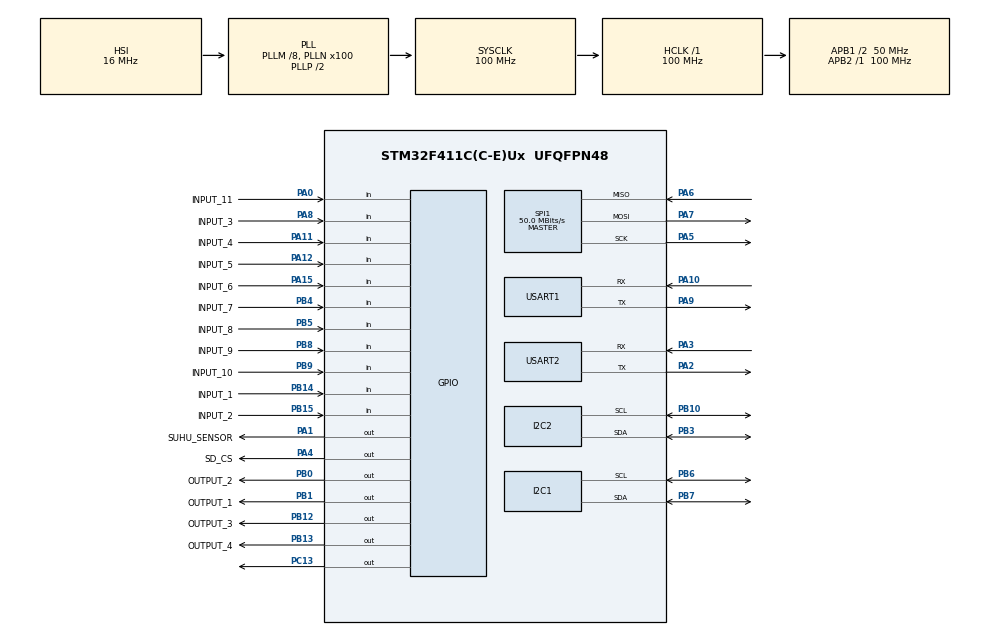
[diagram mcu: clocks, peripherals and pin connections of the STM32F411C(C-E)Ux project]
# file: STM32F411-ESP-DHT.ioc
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FATFS._MAX_SS=4096
FATFS._USE_LFN=1
IWDG.Prescaler=IWDG_PRESCALER_64
IWDG.Reload=999
Mcu.Family=STM32F4
Mcu.Name=STM32F411C(C-E)Ux
Mcu.Package=UFQFPN48
NVIC.I2C1_ER_IRQn=true\:0\:0\:false\:false\:true\:true\:true\:true
NVIC.I2C1_EV_IRQn=true\:0\:0\:false\:false\:true\:true\:true\:true
NVIC.PriorityGroup=NVIC_PRIORITYGROUP_4
NVIC.USART1_IRQn=true\:0\:0\:false\:false\:true\:true\:true\:true
NVIC.USART2_IRQn=true\:0\:0\:false\:false\:true\:true\:true\:true
PA0-WKUP.GPIO_Label=INPUT_11
PA0-WKUP.GPIO_PuPd=GPIO_PULLUP
PA0-WKUP.Signal=GPIO_Input
PA1.GPIO_Label=SUHU_SENSOR
PA1.GPIO_PuPd=GPIO_PULLUP
PA1.Signal=GPIO_Output
PA10.Mode=Asynchronous
PA10.Signal=USART1_RX
PA11.GPIO_Label=INPUT_4
PA11.GPIO_PuPd=GPIO_PULLUP
PA11.Signal=GPIO_Input
PA12.GPIO_Label=INPUT_5
PA12.GPIO_PuPd=GPIO_PULLUP
PA12.Signal=GPIO_Input
PA13.Mode=Serial_Wire
PA13.Signal=SYS_JTMS-SWDIO
PA14.Mode=Serial_Wire
PA14.Signal=SYS_JTCK-SWCLK
PA15.GPIO_Label=INPUT_6
PA15.GPIO_PuPd=GPIO_PULLUP
PA15.Signal=GPIO_Input
PA2.Mode=Asynchronous
PA2.Signal=USART2_TX
PA3.Mode=Asynchronous
PA3.Signal=USART2_RX
PA4.GPIO_Label=SD_CS
PA4.PinState=GPIO_PIN_SET
PA4.Signal=GPIO_Output
PA5.Mode=Full_Duplex_Master
PA5.Signal=SPI1_SCK
PA6.Mode=Full_Duplex_Master
PA6.Signal=SPI1_MISO
PA7.Mode=Full_Duplex_Master
PA7.Signal=SPI1_MOSI
PA8.GPIO_Label=INPUT_3
PA8.GPIO_PuPd=GPIO_PULLUP
PA8.Signal=GPIO_Input
PA9.Mode=Asynchronous
PA9.Signal=USART1_TX
PB0.GPIO_Label=OUTPUT_2
PB0.Signal=GPIO_Output
PB1.GPIO_Label=OUTPUT_1
PB1.Signal=GPIO_Output
PB10.Mode=I2C
PB10.Signal=I2C2_SCL
PB12.GPIO_Label=OUTPUT_3
PB12.Signal=GPIO_Output
PB13.GPIO_Label=OUTPUT_4
PB13.Signal=GPIO_Output
PB14.GPIO_Label=INPUT_1
PB14.GPIO_PuPd=GPIO_PULLUP
PB14.Signal=GPIO_Input
PB15.GPIO_Label=INPUT_2
PB15.GPIO_PuPd=GPIO_PULLUP
PB15.Signal=GPIO_Input
PB3.Mode=I2C
PB3.Signal=I2C2_SDA
PB4.GPIO_Label=INPUT_7
PB4.GPIO_PuPd=GPIO_PULLUP
PB4.Signal=GPIO_Input
PB5.GPIO_Label=INPUT_8
PB5.GPIO_PuPd=GPIO_PULLUP
PB5.Signal=GPIO_Input
PB6.Mode=I2C
PB6.Signal=I2C1_SCL
PB7.Mode=I2C
PB7.Signal=I2C1_SDA
PB8.GPIO_Label=INPUT_9
PB8.GPIO_PuPd=GPIO_PULLUP
PB8.Signal=GPIO_Input
PB9.GPIO_Label=INPUT_10
PB9.GPIO_PuPd=GPIO_PULLUP
PB9.Signal=GPIO_Input
PC13-ANTI_TAMP.Signal=GPIO_Output
PH0\ -\ OSC_IN.Mode=HSE-External-Oscillator
PH0\ -\ OSC_IN.Signal=RCC_OSC_IN
PH1\ -\ OSC_OUT.Mode=HSE-External-Oscillator
PH1\ -\ OSC_OUT.Signal=RCC_OSC_OUT
ProjectManager.HeapSize=0x200
ProjectManager.StackSize=0x400
ProjectManager.TargetToolchain=STM32CubeIDE
RCC.48MHZClocksFreq_Value=50000000
RCC.AHBFreq_Value=100000000
RCC.APB1CLKDivider=RCC_HCLK_DIV2
RCC.APB1Freq_Value=50000000
RCC.APB1TimFreq_Value=100000000
RCC.APB2Freq_Value=100000000
RCC.APB2TimFreq_Value=100000000
RCC.CortexFreq_Value=100000000
RCC.HCLKFreq_Value=100000000
RCC.HSE_VALUE=25000000
RCC.HSI_VALUE=16000000
RCC.LSE_VALUE=32768
RCC.PLLM=8
RCC.PLLN=100
RCC.SYSCLKFreq_VALUE=100000000
RCC.SYSCLKSource=RCC_SYSCLKSOURCE_PLLCLK
RCC.VCOOutputFreq_Value=200000000
SPI1.CalculateBaudRate=50.0 MBits/s
SPI1.Direction=SPI_DIRECTION_2LINES
SPI1.Mode=SPI_MODE_MASTER
SPI1.VirtualType=VM_MASTER
USART1.VirtualMode=VM_ASYNC
USART2.VirtualMode=VM_ASYNC
VP_FATFS_VS_Generic.Mode=User_defined
VP_IWDG_VS_IWDG.Mode=IWDG_Activate
board=custom

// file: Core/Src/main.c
/* USER CODE BEGIN Header */
/**
  ******************************************************************************
  * @file           : main.c
  * @brief          : Main program body
  ******************************************************************************
  * @attention
  *
  * Copyright (c) 2025 STMicroelectronics.
  * All rights reserved.
  *
  * This software is licensed under terms that can be found in the LICENSE file
  * in the root directory of this software component.
  * If no LICENSE file comes with this software, it is provided AS-IS.
  *
  ******************************************************************************
  */
/* USER CODE END Header */
#include "main.h"
#include "fatfs.h"

/* USER CODE BEGIN Includes */
#include <stdio.h>
#include <string.h>
#include <stdlib.h>
#include <stdbool.h>

/* USER CODE END Includes */

/* USER CODE BEGIN PTD */

/* USER CODE BEGIN First_Private_Defines */
#define NUM_ANALOG  4U
#define NUM_INPUTS  11U
#define NUM_OUTPUTS 4U

/* ---- Addon Ekspansi Input (PCF8574, dibaca & dikirim oleh ESP32) ----
 * Konvensi bit gabungan (disepakati dengan firmware ESP32):
 *   bit 0..10  -> I1..I11   (native GPIO STM32, lihat g_inputs[])
 *   bit 11..18 -> I12..I19  (addon PCF8574, dikirim ESP32 via FRAME_TYPE_ADDON)
 */
#define NUM_ADDON_INPUTS       8U
#define ADDON_INPUT_BIT_OFFSET 11U
#define NUM_INPUTS_TOTAL       (ADDON_INPUT_BIT_OFFSET + NUM_ADDON_INPUTS)  /* = 19 */
/* USER CODE END First_Private_Defines */

/* DS3231 RTC Time Structure */
typedef struct
{
    uint8_t  seconds;
    uint8_t  minutes;
    uint8_t  hours;
    uint8_t  dayOfWeek;
    uint8_t  day;
    uint8_t  month;
    uint16_t year;
} DS3231_TimeTypeDef;

/* GPIO Pin Definition */
typedef struct {
    GPIO_TypeDef *Port;
    uint16_t      Pin;
} IO_PinDef_t;

/* Input Index Enum */
typedef enum {
    IN_1 = 0, IN_2, IN_3, IN_4, IN_5,
    IN_6, IN_7, IN_8, IN_9, IN_10, IN_11
} InputId_t;

/* Output Index Enum */
typedef enum {
    OUT_1 = 0, OUT_2, OUT_3, OUT_4
} OutputId_t;

/* Rule Logic Enum */
typedef enum {
    RULE_LOGIC_OFF = 0,
    RULE_LOGIC_OR,
    RULE_LOGIC_AND,
    RULE_LOGIC_NOT
} RuleLogic_t;

/* Rule Definition */
typedef struct {
    RuleLogic_t logic;
    uint8_t     inputs[NUM_INPUTS_TOTAL];  /* referensi input bisa I1..I20 */
    uint8_t     inputCount;
} RuleDef_t;

/* Measurement Structure */
typedef struct {
    uint32_t           seq;
    DS3231_TimeTypeDef rtc;
    int16_t            temp;        		// °C × 10
    int16_t            hum;        			// % × 10
    uint32_t           dig_in;      		// bitmask, bit0..19 = I1..I20 (lihat NUM_INPUTS_TOTAL)
    uint16_t           an_in[NUM_ANALOG];   // 0-255
    uint8_t            q;           		// output bitmask
} Measurement_t;

/* TX Context */
typedef struct {
    uint32_t       seq;
    char           jsonLine[320];
    uint16_t       jsonLen;
    uint8_t        retryCount;
    uint32_t       ackDeadlineMs;
    Measurement_t  measurement;   /* simpan data penuh utk retry TLV identik */
} TxContext_t;

/* Application State */
typedef enum {
    APP_STATE_INIT = 0,
    APP_STATE_SD_MOUNT,
    APP_STATE_LOG_RECOVER,
    APP_STATE_RUN
} AppState_t;

/* TX State */
typedef enum {
    TX_STATE_IDLE = 0,
    TX_STATE_SEND_FRAME,
    TX_STATE_WAIT_TX_COMPLETE,
    TX_STATE_WAIT_ACK,
    TX_STATE_ACK_OK,
    TX_STATE_RETRY_OR_FAIL,
    TX_STATE_MOVE_TO_ERROR
} TxState_t;

typedef struct
{
    uint8_t sensor;
    uint8_t acquisition;
    uint8_t ack;
    uint8_t tx;
    uint8_t sd;
} WatchdogHealth_t;

static WatchdogHealth_t wd;

/* USER CODE END PTD */

/* USER CODE BEGIN PD */
/* ==================== DEBUG CONFIG ====================
 * Master switch untuk SELURUH log debug/monitoring STM32 (mirror dari
 * pola #define DEBUG di firmware ESP32). Ini HANYA mengendalikan log
 * yang keluar lewat UART1 (USB-TTL, dibaca manusia) - TIDAK ada
 * hubungannya dengan komunikasi TLV STM32<->ESP32 di UART2, yang selalu
 * jalan normal terlepas dari nilai DEBUG_ENABLE (lihat UART_Print()
 * vs HAL_UART_Transmit(&huart2, ...) di masing2 fungsi protokol).
 *
 *   DEBUG_ENABLE = 1  -> semua log debug aktif, dikirim ke UART1.
 *   DEBUG_ENABLE = 0  -> seluruh log debug di-strip saat compile time:
 *                        argumen macro (termasuk snprintf & isinya)
 *                        TIDAK dievaluasi sama sekali, jadi tidak ada
 *                        overhead runtime (bukan sekadar if(){} biasa).
 *
 * Cara pakai di kode:
 *   DBG_PRINT("string literal tetap\r\n");
 *   DBG_PRINTF("format %d %s\r\n", angka, teks);
 * Gunakan macro ini utk SEMUA log debug baru, jangan panggil
 * UART_Print()/snprintf(g_debugBuf,...) langsung supaya tetap ikut
 * ter-strip saat DEBUG_ENABLE = 0. */
#define DEBUG_ENABLE 1

#if DEBUG_ENABLE
    #define DBG_PRINT(str)       UART_Print(str)
    #define DBG_PRINTF(fmt, ...) do { snprintf(g_debugBuf, sizeof(g_debugBuf), fmt, ##__VA_ARGS__); \
                                       UART_Print(g_debugBuf); } while (0)
#else
    #define DBG_PRINT(str)       ((void)0)
    #define DBG_PRINTF(fmt, ...) ((void)0)
#endif

/* ==================== TLV FORMAT (UART only) ==================== */
#define TLV_SOF             0x7E

#define TLV_TAG_SEQ         0x01    // uint32 BE
#define TLV_TAG_TEMP        0x02    // int16 BE (°C × 10)
#define TLV_TAG_HUM         0x03    // int16 BE (% × 10)
#define TLV_TAG_DIG_IN      0x04    // uint32 BE (bitmask, bit0..19 = I1..I20 - lihat NUM_INPUTS_TOTAL). BREAKING CHANGE: sebelumnya uint16 (2 byte), sekarang 4 byte - ESP32 wajib update decode-nya juga.
#define TLV_TAG_AN_IN       0x05    // uint16[4] BE
#define TLV_TAG_Q           0x06    // uint8 (bitmask)
#define TLV_TAG_TIMESTAMP   0x07    // uint32 BE

/* Frame types for UART communication */
#define FRAME_TYPE_DATA     0x01
#define FRAME_TYPE_ACK      0x02
#define FRAME_TYPE_RULES    0x03
#define FRAME_TYPE_RTC      0x04
#define FRAME_TYPE_ERROR    0x05   // arah STM32 -> ESP32 (laporan error)
#define FRAME_TYPE_ADDON    0x06   // arah ESP32 -> STM32 (status input addon PCF8574)
#define FRAME_TYPE_READY       0x07   // arah STM32 -> ESP32: STM32 sudah APP_STATE_RUN, siap terima config
#define FRAME_TYPE_RULES_ACK   0x08   // arah STM32 -> ESP32: rules sudah di-parse & diterapkan, payload = jumlah rule

/* TLV tags from ESP32 */
#define TAG_RULE            0x10
#define TAG_RTC_TS          0x20
#define TAG_ADDON_MASK      0x40   // payload 1 byte: bitmask 8 input PCF8574 (aktif=1), lihat FRAME_TYPE_ADDON

/* TLV tags for error report STM32 -> ESP */
#define TLV_TAG_ERR_MODULE  0x30   // u8
#define TLV_TAG_ERR_CODE    0x31   // u8
#define TLV_TAG_ERR_ACTIVE  0x32   // u8 (1 = error, 0 = clear)

/* TLV tag for FRAME_TYPE_RULES_ACK (STM32 -> ESP32) */
#define TAG_RULE_COUNT      0x50   // u8, jumlah rule (Q1..Q4) yg berhasil di-parse & diterapkan

/* I2C Addresses */
#define DS3231_ADDR         (0x68U << 1)
#define ADS1115_ADDR        (0x48U << 1)

/* ADS1115 */
#define ADS_FS_VOLT         4.096f
#define ADC_INPUT_MAX_VOLT  3.3f
#define ADS_READ_PERIOD_MS  100U

/* mid: module id */
#define MOD_RTC   1
#define MOD_DHT   2
#define MOD_ADS   3
#define MOD_SD    4

/* st: status */
#define ST_OK     0
#define ST_ERR    1

/* ec: error code */
#define ERR_NONE      0
#define ERR_TIMEOUT   1
#define ERR_NOT_FOUND 2
#define ERR_CRC       3

/* Buffers */
#define RX_BUF_SIZE             540U
#define UART_FRAME_MAX_LEN      540U
#define JSON_LINE_MAX           320U

/* Timing */
#define INPUT_CHANGE_TIME_MS    500U
#define DELIVERY_TIME_INTERVAL  60000U
#define TX_MAX_RETRY            3U
/* PENTING: nilai ini HARUS lebih besar dari waktu round-trip cloud
 * terlama yang mungkin dipakai ESP32 (lihat sendByTransport() di
 * firmware ESP32). Transport GSM+HTTP butuh ~35-40 detik best-case
 * (HTTPINIT + PARA + prompt + confirm + HTTPACTION 15s + HTTPREAD).
 * Kalau STM32 timeout (retry) SEBELUM ESP32 sempat membalas ACK,
 * STM32 akan kirim ulang TLV yang sama sementara ESP32 masih
 * mem-blocking-proses pengiriman sebelumnya ke cloud -> pengiriman
 * DUPLIKAT ke cloud untuk seq yang sama. 5000ms lama sekali TIDAK
 * cukup untuk mode GSM/HTTP. Sesuaikan angka ini dgn transport
 * TERLAMA yang benar2 dipakai di lapangan; kalau hanya WS/MQTT/TCP
 * (dengan ACK_TIMEOUT_MS versi ESP32 = 3000ms) nilai lama 5000ms
 * cukup - tapi untuk instalasi yang memakai mode GSM/HTTP, WAJIB
 * dinaikkan, dan idempotency di sisi Cloud (dedup by device_id+seq)
 * tetap wajib ada sebagai lapisan pertahanan terakhir. */
#define ACK_TIMEOUT_MS          45000U

/* DHT error reporting delay */
#define DHT_ERROR_ENABLE_DELAY_MS   5000U   // 5 detik setelah boot

/* SD status monitor*/
#define SD_STATUS_INTERVAL_MS   8000U

/* Rules */
#define RULE_MAX_PAYLOAD        420U
#define RULE_STR_MAX_LEN        100U

/* File names*/
#define LOG_FILE_NAME           "log.json"
#define STATUS_FILE_NAME        "status.json"
#define SEQ_FILE_NAME           "seq.dat"      /* counter persisten, independen dari isi queue */
#define LOG_BAD_FILE_NAME       "log_bad.json" /* karantina baris log.json yang gagal di-parse saat recovery */

/* Emergency RAM buffer - fallback TERAKHIR saat SD tidak ter-mount DAN TX
 * sedang sibuk (baru bisa terjadi kalau SD memang lepas/rusak). Ini BUKAN
 * pengganti SD; hanya mencegah 1-2 event terbuang percuma saat window kecil
 * itu terjadi. Kalau SD kembali mount, isi buffer ini di-flush ke log.json. */
#define EMERGENCY_BUF_SLOTS     8U

/* USER CODE END PD */

I2C_HandleTypeDef hi2c1;
I2C_HandleTypeDef hi2c2;

IWDG_HandleTypeDef hiwdg;

SPI_HandleTypeDef hspi1;

UART_HandleTypeDef huart1;
UART_HandleTypeDef huart2;

/* USER CODE BEGIN PV */

/* Sensor data */
static float     g_temp = 0.0f;
static float     g_hum  = 0.0f;
static char      g_debugBuf[384];
static uint32_t  g_bootMs = 0;

/* Input state */
static volatile uint32_t g_inputMaskStable = 0;  /* gabungan I1..I20 (native | addon<<12), dipakai rule engine & dig_in */
static volatile uint16_t g_nativeInputMask = 0;  /* komponen native GPIO saja (I1..I11), didebounce di App_BackgroundSensors */
static volatile uint8_t  g_addonInputMask  = 0;  /* komponen addon PCF8574 (I13..I20), diterima via FRAME_TYPE_ADDON, sudah didebounce di ESP32 */
static volatile uint8_t  g_ruleUpdated     = 0;

/* ---- Addon Type detection ----
 * ESP32 HANYA mengirim frame FRAME_TYPE_ADDON (mask PCF8574) ketika
 * config.addon.type == "ekspansi_input" (lihat handleAddonExpansion() pada
 * firmware ESP32, yang men-skip addonExpansionLoop() untuk addon type
 * "none"/"gsm"). Karena itu, kedatangan frame ini adalah sinyal yang bisa
 * dipakai STM32 untuk mengetahui Addon Type yang sedang aktif TANPA perlu
 * menambah TLV/frame baru pada protokol UART:
 *   - belum pernah terima FRAME_TYPE_ADDON -> Addon Type = None/GSM -> 11 input
 *   - sudah pernah terima FRAME_TYPE_ADDON -> Addon Type = Expansion Input -> 19 input
 */
static volatile uint8_t  g_addonExpansionActive = 0;

/* ADS1115 */
static int16_t  g_anRaw[NUM_ANALOG];
static uint8_t  g_anCache[NUM_ANALOG];
static uint32_t g_adsTick = 0;

/* UART RX - ESP32 */
static uint8_t  g_rxByte;
static uint8_t  g_frameBuf[RX_BUF_SIZE];
static uint16_t g_frameIdx      = 0;
static int16_t  g_expectedLen   = -1;

/* UART RX - RS485/Debug */
static uint8_t  g_rs485RxByte;
static uint8_t  g_rs485Buf[128];
static uint16_t g_rs485Idx = 0;

/* Application state */
static AppState_t g_appState = APP_STATE_SD_MOUNT;

/* SD Card */
static uint8_t  g_sd_mounted = 0;
static uint32_t g_nextSeq    = 1;

/* Flags */
volatile uint8_t g_io_changed_flag = 0;

/* ACK from ESP32 */
volatile uint8_t  g_ack_pending = 0;
volatile uint32_t g_ack_seq     = 0;

/* TX state machine */
static TxState_t   g_txState = TX_STATE_IDLE;
static TxContext_t g_txCtx;
static uint32_t g_pendingLogCount = 0;
static uint32_t g_lastFailedSeq = 0;
static uint32_t g_lastFailedTick = 0;

/* Emergency RAM buffer - lihat komentar EMERGENCY_BUF_SLOTS di atas.
 * HILANG saat power loss (RAM), jadi ini cuma jaring pengaman sekunder;
 * SD card tetap satu-satunya source of truth resmi. */
static Measurement_t g_emergencyBuf[EMERGENCY_BUF_SLOTS];
static uint8_t        g_emergencyCount = 0;

/* Deferred UART Frame Processing - RING BUFFER (bukan 1 slot lagi)
 * Sebelumnya cuma 1 slot: kalau ada frame baru datang sebelum main loop
 * sempat memproses frame sebelumnya (mis. saat STM32 masih di
 * APP_STATE_SD_MOUNT/APP_STATE_LOG_RECOVER dan UART_ProcessPendingFrame()
 * belum dipanggil), frame itu DIBUANG DIAM-DIAM oleh ISR (lihat guard
 * `if (!g_deferredFramePending)` yg lama). Ini salah satu penyebab Rules
 * kadang tidak sampai saat boot bersamaan ESP32+STM32. Sekarang pakai
 * ring buffer kecil supaya beberapa frame yg datang berdekatan (mis. RULES
 * lalu RTC saat boot) tidak saling menimpa. */
#define DEFERRED_FRAME_SLOTS    4U
typedef struct {
    uint8_t  buf[UART_FRAME_MAX_LEN];
    uint16_t len;
    uint8_t  type;
} DeferredFrame_t;
static volatile DeferredFrame_t g_deferredFrames[DEFERRED_FRAME_SLOTS];
static volatile uint8_t g_deferredHead  = 0; /* index utk pop (main loop) */
static volatile uint8_t g_deferredTail  = 0; /* index utk push (ISR) */
static volatile uint8_t g_deferredCount = 0;
static volatile uint32_t g_deferredDroppedCount = 0; /* diagnostik: ring buffer penuh */

/* Error flags */
static uint8_t g_err_rtc = 0;
static uint8_t g_err_dht = 0;
static uint8_t g_err_ads = 0;
static uint8_t g_err_sd  = 0;

/* Input mapping */
static const IO_PinDef_t g_inputs[NUM_INPUTS] =
{
    [IN_1]  = { INPUT_1_GPIO_Port,  INPUT_1_Pin  },
    [IN_2]  = { INPUT_2_GPIO_Port,  INPUT_2_Pin  },
    [IN_3]  = { INPUT_3_GPIO_Port,  INPUT_3_Pin  },
    [IN_4]  = { INPUT_4_GPIO_Port,  INPUT_4_Pin  },
    [IN_5]  = { INPUT_5_GPIO_Port,  INPUT_5_Pin  },
    [IN_6]  = { INPUT_6_GPIO_Port,  INPUT_6_Pin  },
    [IN_7]  = { INPUT_7_GPIO_Port,  INPUT_7_Pin  },
    [IN_8]  = { INPUT_8_GPIO_Port,  INPUT_8_Pin  },
    [IN_9]  = { INPUT_9_GPIO_Port,  INPUT_9_Pin  },
    [IN_10] = { INPUT_10_GPIO_Port, INPUT_10_Pin },
    [IN_11] = { INPUT_11_GPIO_Port, INPUT_11_Pin }
};

/* Output mapping */
static const IO_PinDef_t g_outputs[NUM_OUTPUTS] = {
    [OUT_1] = { OUTPUT_1_GPIO_Port, OUTPUT_1_Pin },
    [OUT_2] = { OUTPUT_2_GPIO_Port, OUTPUT_2_Pin },
    [OUT_3] = { OUTPUT_3_GPIO_Port, OUTPUT_3_Pin },
    [OUT_4] = { OUTPUT_4_GPIO_Port, OUTPUT_4_Pin }
};

/* Rules */
static RuleDef_t g_rules[NUM_OUTPUTS];

/* USER CODE END PV */

void SystemClock_Config(void);
static void MX_GPIO_Init(void);
static void MX_USART1_UART_Init(void);
static void MX_USART2_UART_Init(void);
static void MX_I2C1_Init(void);
static void MX_I2C2_Init(void);
static void MX_SPI1_Init(void);
static void MX_IWDG_Init(void);
/* USER CODE BEGIN PFP */

/* Utility */
static void UART_Print(const char* str);

/* DHT22 */
void DWT_Delay_Init(void);
void delay_us(uint32_t us);
void DHT_SetOutput(void);
void DHT_SetInput(void);
uint8_t DHT_Start(void);
uint8_t DHT_ReadBit(void);
uint8_t DHT_ReadByte(void);
uint8_t DHT22_Read(float *temperature, float *humidity);

/* DS3231 RTC */
static uint8_t bcd2bin(uint8_t val);
static uint8_t bin2bcd(uint8_t val);
uint8_t DS3231_ReadTime(DS3231_TimeTypeDef *t);
uint8_t DS3231_SetTime(const DS3231_TimeTypeDef *t);
static uint8_t IsLeapYear(uint16_t year);
static uint32_t RTC_ToEpochSeconds(const DS3231_TimeTypeDef *t);
static void EpochToRTC(uint32_t epoch, DS3231_TimeTypeDef *t);

/* ADS1115 */
static int16_t ADS1115_ReadRaw(uint8_t ch);
static float ADS1115_ConvertRawToVolt(int16_t raw);
static void ADS_Task(void);
static uint8_t VoltageToPWM_0_255(float voltage);

/* CRC */
static uint16_t CRC16_Modbus(const uint8_t *data, uint16_t len);

/* TLV Encoder (for UART TX to ESP32) */
static size_t TLV_PutU8(uint8_t *buf, uint8_t tag, uint8_t val);
static size_t TLV_PutU16(uint8_t *buf, uint8_t tag, uint16_t val);
static size_t TLV_PutI16(uint8_t *buf, uint8_t tag, int16_t val);
static size_t TLV_PutU32(uint8_t *buf, uint8_t tag, uint32_t val);
static size_t TLV_PutU16Array4(uint8_t *buf, uint8_t tag, const uint16_t arr[4]);
static size_t TLV_EncodeMeasurement(const Measurement_t *m, uint8_t *out, size_t maxLen);
static void SendErrorTLV(uint8_t mid, uint8_t st, uint8_t ec);
static void SendReadyTLV(void);
static void SendRulesAckTLV(uint8_t ruleCount);

/* TLV Parser (from ESP32) */
static uint32_t TLV_ReadU32BE(const uint8_t *p);

/* JSON Encoder/Parser (for SD Card log & debug) */
static size_t JSON_EncodeMeasurement(const Measurement_t *m, char *out, size_t maxLen);
static bool JSON_ParseSeqFromLine(const char *line, uint32_t *outSeq);

/* Rules & Frame RX */
void HAL_UART_RxCpltCallback(UART_HandleTypeDef *huart);
static void Rules_Reset(void);
static void ParseOneRuleString(const char *ruleStr);
static void ParseRulesTLV(const uint8_t *tlv, size_t len);
static void ParseRTCTLV(const uint8_t *tlv, size_t len);
static void ParseACKTLV(const uint8_t *tlv, size_t len);
static void ParseAddonTLV(const uint8_t *tlv, size_t len);
static void RecomputeCombinedInputMask(void);
static inline uint8_t Addon_ActiveInputCount(void);
static uint8_t EvalOutputState(int qIdx, uint32_t inputMask);
static void ApplyRules(uint32_t inputMask);
static void PrintRuleStatus(void);
static void OnFrameReceived(uint8_t *payload, uint16_t len, uint8_t frameType);

/* Logging / ACK helper */
static bool Log_RemoveSeq(uint32_t seqToRemove);
static bool SendMeasurementTLV(const Measurement_t *m);

/* TX state machine */
static void TX_StartNew(const Measurement_t *m);
static void TX_Process(uint32_t now);

/* SD Card & Log (JSON format) */
static void Log_InitRuntime(void);
static bool SD_MountTask(void);
static bool Log_RecoverTask(void);
static bool Log_AppendJSON(const char *jsonLine);
static bool Seq_LoadPersisted(uint32_t *outSeq);
static bool Seq_Persist(uint32_t nextSeq);
static void Log_QuarantineBadLines(void);
static void Emergency_Push(const Measurement_t *m);
static void Emergency_FlushToSD(void);
static void SD_StatusTask(uint32_t now);

/* Application */
static void App_BackgroundSensors(uint32_t now);
static void App_HandleAcquisition(uint32_t now);
static void Acquire_FillMeasurement(Measurement_t *m, const DS3231_TimeTypeDef *rtc);
static void UART_ProcessPendingFrame(void);

/* Debug */
static void Debug_ErrorJson(uint8_t mid, uint8_t st, uint8_t ec);
static void Debug_PrintMeasurementJSON(const Measurement_t *m, bool byIo);
static void Debug_DumpTLV(const char *prefix, const uint8_t *tlv, size_t len);

static void WD_Service(void);

/* USER CODE END PFP */

/* USER CODE BEGIN 0 */

/* ==================== UTILITY ==================== */
static void UART_Print(const char* str)
{
    HAL_UART_Transmit(&huart1, (uint8_t *)str, strlen(str), 100);
}

static inline void WD_SetSensor(void)
{
    wd.sensor = 1;
}

static inline void WD_SetAcquisition(void)
{
    wd.acquisition = 1;
}

static inline void WD_SetAck(void)
{
    wd.ack = 1;
}

static inline void WD_SetTX(void)
{
    wd.tx = 1;
}

static inline void WD_SetSD(void)
{
    wd.sd = 1;
}

/* USER CODE END 0 */

int main(void)
{

  /* MCU Configuration--------------------------------------------------------*/

  /* Reset of all peripherals, Initializes the Flash interface and the Systick. */
  HAL_Init();

  /* Configure the system clock */
  SystemClock_Config();

  /* USER CODE BEGIN SysInit */

  DWT_Delay_Init();
  g_bootMs = HAL_GetTick();   // simpan waktu boot untuk referensi DHT
  /* USER CODE END SysInit */

  /* Initialize all configured peripherals */
  MX_GPIO_Init();
  MX_USART1_UART_Init();
  MX_USART2_UART_Init();
  MX_I2C1_Init();
  MX_I2C2_Init();
  MX_SPI1_Init();
  MX_FATFS_Init();
  MX_IWDG_Init();
  /* USER CODE BEGIN 2 */

  DBG_PRINT("\r\n");
  DBG_PRINT("============================================\r\n");
  DBG_PRINT("  STM32 IoT Node - TLV/JSON Hybrid v1.0\r\n");
  DBG_PRINT("  UART Comms : TLV Binary\r\n");
  DBG_PRINT("  SD Card    : JSON (Human-readable)\r\n");
  DBG_PRINT("  Debug      : JSON (Human-readable)\r\n");
  DBG_PRINT("============================================\r\n");

  Log_InitRuntime();
  g_appState = APP_STATE_SD_MOUNT;

  /* USER CODE END 2 */

  /* Infinite loop */
  /* USER CODE BEGIN WHILE */
  while (1)
  {
      uint32_t now = HAL_GetTick();

      switch (g_appState)
      {
      case APP_STATE_SD_MOUNT:
          {
              uint8_t tries = 0;
              while (!g_sd_mounted && tries < 3) {
                  SD_MountTask();
                  HAL_Delay(200); // jeda 200ms antar percobaan awal
                  tries++;
              }
              g_appState = APP_STATE_LOG_RECOVER;
          }
          break;

      case APP_STATE_LOG_RECOVER:
          // Kalau SD sudah ter-mount, lakukan recovery; kalau tidak, skip saja
          if (g_sd_mounted) {
              Log_RecoverTask();
          }
          g_appState = APP_STATE_RUN;
          DBG_PRINT("[APP] Entering RUN state\r\n");
          /* STM32 baru sekarang benar2 siap: UART_ProcessPendingFrame()
             akan mulai dipanggil di iterasi berikutnya. Kabari ESP32
             lewat handshake FRAME_TYPE_READY, supaya ESP32 tahu KAPAN
             aman mengirim Rules - bukan lagi menebak pakai delay tetap
             yg jadi akar penyebab race saat boot bersamaan. */
          SendReadyTLV();
          break;

      case APP_STATE_RUN:
          // Di RUN, kalau belum ada SD, coba mount berkala (user colok saat jalan)
          if (!g_sd_mounted) {
              SD_MountTask();
          }

          App_BackgroundSensors(now);
          WD_SetSensor();

          App_HandleAcquisition(now);
          WD_SetAcquisition();

          UART_ProcessPendingFrame();
          wd.ack = 1;

          TX_Process(now);
          WD_SetTX();

          SD_StatusTask(now);
          WD_SetSD();

          WD_Service();

          break;

      default:
          g_appState = APP_STATE_SD_MOUNT;
          break;
      }

      HAL_Delay(1);
    /* USER CODE END WHILE */

  }
}

void SystemClock_Config(void)
{
  RCC_OscInitTypeDef RCC_OscInitStruct = {0};
  RCC_ClkInitTypeDef RCC_ClkInitStruct = {0};

  /** Configure the main internal regulator output voltage
  */
  __HAL_RCC_PWR_CLK_ENABLE();
  __HAL_PWR_VOLTAGESCALING_CONFIG(PWR_REGULATOR_VOLTAGE_SCALE1);

  /** Initializes the RCC Oscillators according to the specified parameters
  * in the RCC_OscInitTypeDef structure.
  */
  RCC_OscInitStruct.OscillatorType = RCC_OSCILLATORTYPE_HSI|RCC_OSCILLATORTYPE_LSI;
  RCC_OscInitStruct.HSIState = RCC_HSI_ON;
  RCC_OscInitStruct.HSICalibrationValue = RCC_HSICALIBRATION_DEFAULT;
  RCC_OscInitStruct.LSIState = RCC_LSI_ON;
  RCC_OscInitStruct.PLL.PLLState = RCC_PLL_ON;
  RCC_OscInitStruct.PLL.PLLSource = RCC_PLLSOURCE_HSI;
  RCC_OscInitStruct.PLL.PLLM = 8;
  RCC_OscInitStruct.PLL.PLLN = 100;
  RCC_OscInitStruct.PLL.PLLP = RCC_PLLP_DIV2;
  RCC_OscInitStruct.PLL.PLLQ = 4;
  if (HAL_RCC_OscConfig(&RCC_OscInitStruct) != HAL_OK)
  {
    Error_Handler();
  }

  /** Initializes the CPU, AHB and APB buses clocks
  */
  RCC_ClkInitStruct.ClockType = RCC_CLOCKTYPE_HCLK|RCC_CLOCKTYPE_SYSCLK
                              |RCC_CLOCKTYPE_PCLK1|RCC_CLOCKTYPE_PCLK2;
  RCC_ClkInitStruct.SYSCLKSource = RCC_SYSCLKSOURCE_PLLCLK;
  RCC_ClkInitStruct.AHBCLKDivider = RCC_SYSCLK_DIV1;
  RCC_ClkInitStruct.APB1CLKDivider = RCC_HCLK_DIV2;
  RCC_ClkInitStruct.APB2CLKDivider = RCC_HCLK_DIV1;

  if (HAL_RCC_ClockConfig(&RCC_ClkInitStruct, FLASH_LATENCY_3) != HAL_OK)
  {
    Error_Handler();
  }
}

static void MX_I2C1_Init(void)
{

  hi2c1.Instance = I2C1;
  hi2c1.Init.ClockSpeed = 100000;
  hi2c1.Init.DutyCycle = I2C_DUTYCYCLE_2;
  hi2c1.Init.OwnAddress1 = 0;
  hi2c1.Init.AddressingMode = I2C_ADDRESSINGMODE_7BIT;
  hi2c1.Init.DualAddressMode = I2C_DUALADDRESS_DISABLE;
  hi2c1.Init.OwnAddress2 = 0;
  hi2c1.Init.GeneralCallMode = I2C_GENERALCALL_DISABLE;
  hi2c1.Init.NoStretchMode = I2C_NOSTRETCH_DISABLE;
  if (HAL_I2C_Init(&hi2c1) != HAL_OK)
  {
    Error_Handler();
  }

}

static void MX_I2C2_Init(void)
{

  hi2c2.Instance = I2C2;
  hi2c2.Init.ClockSpeed = 100000;
  hi2c2.Init.DutyCycle = I2C_DUTYCYCLE_2;
  hi2c2.Init.OwnAddress1 = 0;
  hi2c2.Init.AddressingMode = I2C_ADDRESSINGMODE_7BIT;
  hi2c2.Init.DualAddressMode = I2C_DUALADDRESS_DISABLE;
  hi2c2.Init.OwnAddress2 = 0;
  hi2c2.Init.GeneralCallMode = I2C_GENERALCALL_DISABLE;
  hi2c2.Init.NoStretchMode = I2C_NOSTRETCH_DISABLE;
  if (HAL_I2C_Init(&hi2c2) != HAL_OK)
  {
    Error_Handler();
  }

}

static void MX_IWDG_Init(void)
{

  hiwdg.Instance = IWDG;
  hiwdg.Init.Prescaler = IWDG_PRESCALER_64;
  hiwdg.Init.Reload = 999;
  if (HAL_IWDG_Init(&hiwdg) != HAL_OK)
  {
    Error_Handler();
  }

}

static void MX_SPI1_Init(void)
{

  /* SPI1 parameter configuration*/
  hspi1.Instance = SPI1;
  hspi1.Init.Mode = SPI_MODE_MASTER;
  hspi1.Init.Direction = SPI_DIRECTION_2LINES;
  hspi1.Init.DataSize = SPI_DATASIZE_8BIT;
  hspi1.Init.CLKPolarity = SPI_POLARITY_LOW;
  hspi1.Init.CLKPhase = SPI_PHASE_1EDGE;
  hspi1.Init.NSS = SPI_NSS_SOFT;
  hspi1.Init.BaudRatePrescaler = SPI_BAUDRATEPRESCALER_2;
  hspi1.Init.FirstBit = SPI_FIRSTBIT_MSB;
  hspi1.Init.TIMode = SPI_TIMODE_DISABLE;
  hspi1.Init.CRCCalculation = SPI_CRCCALCULATION_DISABLE;
  hspi1.Init.CRCPolynomial = 10;
  if (HAL_SPI_Init(&hspi1) != HAL_OK)
  {
    Error_Handler();
  }

}

static void MX_USART1_UART_Init(void)
{

  huart1.Instance = USART1;
  huart1.Init.BaudRate = 115200;
  huart1.Init.WordLength = UART_WORDLENGTH_8B;
  huart1.Init.StopBits = UART_STOPBITS_1;
  huart1.Init.Parity = UART_PARITY_NONE;
  huart1.Init.Mode = UART_MODE_TX_RX;
  huart1.Init.HwFlowCtl = UART_HWCONTROL_NONE;
  huart1.Init.OverSampling = UART_OVERSAMPLING_16;
  if (HAL_UART_Init(&huart1) != HAL_OK)
  {
    Error_Handler();
  }
  /* USER CODE BEGIN USART1_Init 2 */
  HAL_UART_Receive_IT(&huart1, &g_rs485RxByte, 1);

  /* Priority lebih rendah dari USART2 (yg di-set 5,0) - RS485/debug
     tidak boleh starvasi link data kritis ke ESP32 saat dua interrupt
     datang berdekatan. Angka NVIC lebih besar = priority eksekusi
     lebih rendah di Cortex-M. */
  HAL_NVIC_SetPriority(USART1_IRQn, 6, 0);
  HAL_NVIC_EnableIRQ(USART1_IRQn);
  /* USER CODE END USART1_Init 2 */

}

static void MX_USART2_UART_Init(void)
{

  huart2.Instance = USART2;
  huart2.Init.BaudRate = 115200;
  huart2.Init.WordLength = UART_WORDLENGTH_8B;
  huart2.Init.StopBits = UART_STOPBITS_1;
  huart2.Init.Parity = UART_PARITY_NONE;
  huart2.Init.Mode = UART_MODE_TX_RX;
  huart2.Init.HwFlowCtl = UART_HWCONTROL_NONE;
  huart2.Init.OverSampling = UART_OVERSAMPLING_16;
  if (HAL_UART_Init(&huart2) != HAL_OK)
  {
    Error_Handler();
  }
  /* USER CODE BEGIN USART2_Init 2 */
  	HAL_UART_Receive_IT(&huart2, &g_rxByte, 1);

  	HAL_NVIC_SetPriority(USART2_IRQn, 5, 0);
  	HAL_NVIC_EnableIRQ(USART2_IRQn);
  /* USER CODE END USART2_Init 2 */

}

static void MX_GPIO_Init(void)
{
  GPIO_InitTypeDef GPIO_InitStruct = {0};

  /* GPIO Ports Clock Enable */
  __HAL_RCC_GPIOC_CLK_ENABLE();
  __HAL_RCC_GPIOH_CLK_ENABLE();
  __HAL_RCC_GPIOA_CLK_ENABLE();
  __HAL_RCC_GPIOB_CLK_ENABLE();

  /*Configure GPIO pin Output Level */
  HAL_GPIO_WritePin(GPIOC, GPIO_PIN_13, GPIO_PIN_RESET);

  /*Configure GPIO pin Output Level */
  HAL_GPIO_WritePin(SUHU_SENSOR_GPIO_Port, SUHU_SENSOR_Pin, GPIO_PIN_RESET);

  /*Configure GPIO pin Output Level */
  HAL_GPIO_WritePin(SD_CS_GPIO_Port, SD_CS_Pin, GPIO_PIN_SET);

  /*Configure GPIO pin Output Level */
  HAL_GPIO_WritePin(GPIOB, OUTPUT_2_Pin|OUTPUT_1_Pin|OUTPUT_3_Pin|OUTPUT_4_Pin, GPIO_PIN_RESET);

  /*Configure GPIO pin : PC13 */
  GPIO_InitStruct.Pin = GPIO_PIN_13;
  GPIO_InitStruct.Mode = GPIO_MODE_OUTPUT_PP;
  GPIO_InitStruct.Pull = GPIO_NOPULL;
  GPIO_InitStruct.Speed = GPIO_SPEED_FREQ_LOW;
  HAL_GPIO_Init(GPIOC, &GPIO_InitStruct);

  /*Configure GPIO pins : INPUT_11_Pin INPUT_3_Pin INPUT_4_Pin INPUT_5_Pin
                           INPUT_6_Pin */
  GPIO_InitStruct.Pin = INPUT_11_Pin|INPUT_3_Pin|INPUT_4_Pin|INPUT_5_Pin
                          |INPUT_6_Pin;
  GPIO_InitStruct.Mode = GPIO_MODE_INPUT;
  GPIO_InitStruct.Pull = GPIO_PULLUP;
  HAL_GPIO_Init(GPIOA, &GPIO_InitStruct);

  /*Configure GPIO pin : SUHU_SENSOR_Pin */
  GPIO_InitStruct.Pin = SUHU_SENSOR_Pin;
  GPIO_InitStruct.Mode = GPIO_MODE_OUTPUT_PP;
  GPIO_InitStruct.Pull = GPIO_PULLUP;
  GPIO_InitStruct.Speed = GPIO_SPEED_FREQ_LOW;
  HAL_GPIO_Init(SUHU_SENSOR_GPIO_Port, &GPIO_InitStruct);

  /*Configure GPIO pin : SD_CS_Pin */
  GPIO_InitStruct.Pin = SD_CS_Pin;
  GPIO_InitStruct.Mode = GPIO_MODE_OUTPUT_PP;
  GPIO_InitStruct.Pull = GPIO_NOPULL;
  GPIO_InitStruct.Speed = GPIO_SPEED_FREQ_LOW;
  HAL_GPIO_Init(SD_CS_GPIO_Port, &GPIO_InitStruct);

  /*Configure GPIO pins : OUTPUT_2_Pin OUTPUT_1_Pin OUTPUT_3_Pin OUTPUT_4_Pin */
  GPIO_InitStruct.Pin = OUTPUT_2_Pin|OUTPUT_1_Pin|OUTPUT_3_Pin|OUTPUT_4_Pin;
  GPIO_InitStruct.Mode = GPIO_MODE_OUTPUT_PP;
  GPIO_InitStruct.Pull = GPIO_NOPULL;
  GPIO_InitStruct.Speed = GPIO_SPEED_FREQ_LOW;
  HAL_GPIO_Init(GPIOB, &GPIO_InitStruct);

  /*Configure GPIO pins : INPUT_1_Pin INPUT_2_Pin INPUT_7_Pin INPUT_8_Pin
                           INPUT_9_Pin INPUT_10_Pin */
  GPIO_InitStruct.Pin = INPUT_1_Pin|INPUT_2_Pin|INPUT_7_Pin|INPUT_8_Pin
                          |INPUT_9_Pin|INPUT_10_Pin;
  GPIO_InitStruct.Mode = GPIO_MODE_INPUT;
  GPIO_InitStruct.Pull = GPIO_PULLUP;
  HAL_GPIO_Init(GPIOB, &GPIO_InitStruct);

}

/* USER CODE BEGIN 4 */

/* ==================== DWT DELAY ==================== */
void DWT_Delay_Init(void)
{
    CoreDebug->DEMCR |= CoreDebug_DEMCR_TRCENA_Msk;
    DWT->CYCCNT = 0;
    DWT->CTRL |= DWT_CTRL_CYCCNTENA_Msk;
}

void delay_us(uint32_t us)
{
    uint32_t cycles = us * (SystemCoreClock / 1000000);
    uint32_t start = DWT->CYCCNT;
    while ((DWT->CYCCNT - start) < cycles);
}

/* ==================== DHT22 DRIVER ==================== */
void DHT_SetOutput(void)
{
    GPIO_InitTypeDef GPIO_InitStruct = {0};
    GPIO_InitStruct.Pin = SUHU_SENSOR_Pin;
    GPIO_InitStruct.Mode = GPIO_MODE_OUTPUT_PP;
    GPIO_InitStruct.Pull = GPIO_NOPULL;
    GPIO_InitStruct.Speed = GPIO_SPEED_FREQ_LOW;
    HAL_GPIO_Init(SUHU_SENSOR_GPIO_Port, &GPIO_InitStruct);
}

void DHT_SetInput(void)
{
    GPIO_InitTypeDef GPIO_InitStruct = {0};
    GPIO_InitStruct.Pin = SUHU_SENSOR_Pin;
    GPIO_InitStruct.Mode = GPIO_MODE_INPUT;
    GPIO_InitStruct.Pull = GPIO_PULLUP;
    HAL_GPIO_Init(SUHU_SENSOR_GPIO_Port, &GPIO_InitStruct);
}

uint8_t DHT_Start(void)
{
    uint32_t timeout;

    DHT_SetOutput();
    HAL_GPIO_WritePin(SUHU_SENSOR_GPIO_Port, SUHU_SENSOR_Pin, GPIO_PIN_RESET);
    HAL_Delay(2);
    HAL_GPIO_WritePin(SUHU_SENSOR_GPIO_Port, SUHU_SENSOR_Pin, GPIO_PIN_SET);
    delay_us(30);
    DHT_SetInput();

    timeout = 0;
    while (HAL_GPIO_ReadPin(SUHU_SENSOR_GPIO_Port, SUHU_SENSOR_Pin) == GPIO_PIN_SET)
    {
        delay_us(1);
        if (++timeout > 200) return 0;
    }

    timeout = 0;
    while (HAL_GPIO_ReadPin(SUHU_SENSOR_GPIO_Port, SUHU_SENSOR_Pin) == GPIO_PIN_RESET)
    {
        delay_us(1);
        if (++timeout > 200) return 0;
    }

    timeout = 0;
    while (HAL_GPIO_ReadPin(SUHU_SENSOR_GPIO_Port, SUHU_SENSOR_Pin) == GPIO_PIN_SET)
    {
        delay_us(1);
        if (++timeout > 200) return 0;
    }

    return 1;
}

uint8_t DHT_ReadBit(void)
{
    uint8_t bit = 0;
    uint32_t timeout = 0;

    // Tunggu naik dari LOW ke HIGH, tapi dengan timeout
    while (HAL_GPIO_ReadPin(SUHU_SENSOR_GPIO_Port, SUHU_SENSOR_Pin) == GPIO_PIN_RESET)
    {
        delay_us(1);
        if (++timeout > 200) {
            // timeout ~200 us, anggap bit = 0 dan keluar
            return 0;
        }
    }

    delay_us(40);
    if (HAL_GPIO_ReadPin(SUHU_SENSOR_GPIO_Port, SUHU_SENSOR_Pin) == GPIO_PIN_SET)
        bit = 1;

    // Tunggu turun kembali ke LOW, juga dengan timeout
    timeout = 0;
    while (HAL_GPIO_ReadPin(SUHU_SENSOR_GPIO_Port, SUHU_SENSOR_Pin) == GPIO_PIN_SET)
    {
        delay_us(1);
        if (++timeout > 200) {
            break;  // paksa keluar supaya tidak hang
        }
    }

    return bit;
}

uint8_t DHT_ReadByte(void)
{
    uint8_t i, data = 0;
    for (i = 0; i < 8; i++)
    {
        data <<= 1;
        data |= DHT_ReadBit();
    }
    return data;
}

uint8_t DHT22_Read(float *temperature, float *humidity)
{
    uint8_t data[5];

    if (!DHT_Start()) return 0;

    data[0] = DHT_ReadByte();
    data[1] = DHT_ReadByte();
    data[2] = DHT_ReadByte();
    data[3] = DHT_ReadByte();
    data[4] = DHT_ReadByte();

    uint8_t sum = data[0] + data[1] + data[2] + data[3];
    if (sum != data[4]) return 0;

    uint16_t rawHum  = (data[0] << 8) | data[1];
    int16_t  rawTemp = (data[2] << 8) | data[3];

    *humidity = rawHum / 10.0f;

    if (rawTemp & 0x8000)
    {
        rawTemp &= 0x7FFF;
        *temperature = -rawTemp / 10.0f;
    }
    else
    {
        *temperature = rawTemp / 10.0f;
    }

    if (*humidity < 0.0f || *humidity > 100.0f) return 0;
    if (*temperature < -40.0f || *temperature > 80.0f) return 0;

    return 1;
}

/* ==================== I2C RECOVERY ==================== */
static void I2C1_RecoverBus(void)
{
    HAL_I2C_DeInit(&hi2c1);
    MX_I2C1_Init();    // re-init peripheral
}

static void I2C2_RecoverBus(void)
{
    HAL_I2C_DeInit(&hi2c2);
    MX_I2C2_Init();    // re-init peripheral
}

/* Map HAL I2C status -> error code */
static uint8_t I2C_StatusToErrCode(HAL_StatusTypeDef st)
{
    if (st == HAL_TIMEOUT) {
        return ERR_TIMEOUT;
    }
    // HAL_ERROR atau HAL_BUSY -> treat as NOT_FOUND (device NACK / hilang)
    return ERR_NOT_FOUND;
}

/* ==================== DS3231 RTC ==================== */
static uint8_t bcd2bin(uint8_t val)
{
    return (uint8_t)((val >> 4) * 10 + (val & 0x0F));
}

static uint8_t bin2bcd(uint8_t val)
{
    return (uint8_t)(((val / 10) << 4) | (val % 10));
}

uint8_t DS3231_ReadTime(DS3231_TimeTypeDef *t)
{
    uint8_t buf[7];
    HAL_StatusTypeDef st;

    st = HAL_I2C_Mem_Read(&hi2c1, DS3231_ADDR, 0x00, I2C_MEMADD_SIZE_8BIT,
                          buf, 7, 100);
    if (st != HAL_OK) {
        // Coba recovery I2C1 sekali
        I2C1_RecoverBus();
        st = HAL_I2C_Mem_Read(&hi2c1, DS3231_ADDR, 0x00, I2C_MEMADD_SIZE_8BIT,
                              buf, 7, 100);
        if (st != HAL_OK) {
            // Biarkan App_HandleAcquisition yang meng-set Debug_ErrorJson/SendErrorTLV
            return 0;
        }
    }

    t->seconds   = bcd2bin(buf[0] & 0x7F);
    t->minutes   = bcd2bin(buf[1] & 0x7F);
    t->hours     = bcd2bin(buf[2] & 0x3F);
    t->dayOfWeek = bcd2bin(buf[3] & 0x07);
    t->day       = bcd2bin(buf[4] & 0x3F);
    t->month     = bcd2bin(buf[5] & 0x1F);
    t->year      = 2000 + bcd2bin(buf[6]);

    return 1;
}

uint8_t DS3231_SetTime(const DS3231_TimeTypeDef *t)
{
    uint8_t buf[7];

    buf[0] = bin2bcd(t->seconds);
    buf[1] = bin2bcd(t->minutes);
    buf[2] = bin2bcd(t->hours);
    buf[3] = bin2bcd(t->dayOfWeek);
    buf[4] = bin2bcd(t->day);
    buf[5] = bin2bcd(t->month);
    buf[6] = bin2bcd((uint8_t)(t->year - 2000));

    if (HAL_I2C_Mem_Write(&hi2c1, DS3231_ADDR, 0x00, I2C_MEMADD_SIZE_8BIT,
                          buf, 7, 100) != HAL_OK)
    {
        return 0;
    }
    return 1;
}

static uint8_t IsLeapYear(uint16_t year)
{
    return (year % 4U == 0U);
}

static uint32_t RTC_ToEpochSeconds(const DS3231_TimeTypeDef *t)
{
    static const uint8_t days_in_month[12] =
        {31,28,31,30,31,30,31,31,30,31,30,31};

    uint32_t days = 0;

    for (uint16_t y = 2000; y < t->year; y++) {
        days += 365U + (IsLeapYear(y) ? 1U : 0U);
    }

    for (uint8_t m = 1; m < t->month; m++) {
        days += days_in_month[m-1];
        if (m == 2 && IsLeapYear(t->year)) {
            days += 1U;
        }
    }

    days += (uint32_t)(t->day - 1U);

    uint32_t seconds =
        days * 86400UL +
        (uint32_t)t->hours   * 3600UL +
        (uint32_t)t->minutes * 60UL  +
        (uint32_t)t->seconds;

    return seconds;
}

static void EpochToRTC(uint32_t epoch, DS3231_TimeTypeDef *t)
{
    static const uint8_t daysInMonth[12] =
        {31,28,31,30,31,30,31,31,30,31,30,31};

    uint32_t days = epoch / 86400;
    uint32_t secs = epoch % 86400;

    t->hours   = secs / 3600;
    t->minutes = (secs % 3600) / 60;
    t->seconds = secs % 60;

    t->year = 2000;
    while (1) {
        uint16_t daysInYear = 365 + (IsLeapYear(t->year) ? 1 : 0);
        if (days < daysInYear) break;
        days -= daysInYear;
        t->year++;
    }

    t->month = 1;
    while (1) {
        uint8_t dim = daysInMonth[t->month - 1];
        if (t->month == 2 && IsLeapYear(t->year)) dim = 29;
        if (days < dim) break;
        days -= dim;
        t->month++;
    }

    t->day = days + 1;
    t->dayOfWeek = 1;
}

/* ==================== ADS1115 DRIVER ==================== */
static int16_t ADS1115_ReadRaw(uint8_t ch)
{
    uint8_t  cfg[3];
    uint8_t  rx[2];
    uint16_t config;
    HAL_StatusTypeDef st;
    uint8_t ec;   // error code

    config  = 0x8000U;
    config |= (uint16_t)((0x04U + ch) << 12);
    config |= 0x0200U;
    config |= 0x0100U;
    config |= 0x0080U;
    config |= 0x0003U;

    cfg[0] = 0x01;
    cfg[1] = (uint8_t)(config >> 8);
    cfg[2] = (uint8_t)(config & 0xFF);

    // TX config
    st = HAL_I2C_Master_Transmit(&hi2c2, ADS1115_ADDR, cfg, 3, 100);
    if (st != HAL_OK) {
        I2C2_RecoverBus();
        st = HAL_I2C_Master_Transmit(&hi2c2, ADS1115_ADDR, cfg, 3, 100);
    }
    if (st != HAL_OK) {
        if (!g_err_ads) {
            g_err_ads = 1;
            ec = I2C_StatusToErrCode(st);   // ERR_TIMEOUT atau ERR_NOT_FOUND
            Debug_ErrorJson(MOD_ADS, ST_ERR, ec);
            SendErrorTLV(MOD_ADS, ST_ERR, ec);
        }
        return 0;
    }

    HAL_Delay(8);

    // Set register pointer ke 0x00
    cfg[0] = 0x00;
    st = HAL_I2C_Master_Transmit(&hi2c2, ADS1115_ADDR, cfg, 1, 100);
    if (st != HAL_OK) {
        I2C2_RecoverBus();
        st = HAL_I2C_Master_Transmit(&hi2c2, ADS1115_ADDR, cfg, 1, 100);
    }
    if (st != HAL_OK) {
        if (!g_err_ads) {
            g_err_ads = 1;
            ec = I2C_StatusToErrCode(st);
            Debug_ErrorJson(MOD_ADS, ST_ERR, ec);
            SendErrorTLV(MOD_ADS, ST_ERR, ec);
        }
        return 0;
    }

    // Read conversion
    st = HAL_I2C_Master_Receive(&hi2c2, ADS1115_ADDR, rx, 2, 100);
    if (st != HAL_OK) {
        I2C2_RecoverBus();
        st = HAL_I2C_Master_Receive(&hi2c2, ADS1115_ADDR, rx, 2, 100);
    }
    if (st != HAL_OK) {
        if (!g_err_ads) {
            g_err_ads = 1;
            ec = I2C_StatusToErrCode(st);
            Debug_ErrorJson(MOD_ADS, ST_ERR, ec);
            SendErrorTLV(MOD_ADS, ST_ERR, ec);
        }
        return 0;
    }

    // Sampai sini semua OK, kalau sebelumnya error, kirim status OK
    if (g_err_ads) {
        g_err_ads = 0;
        Debug_ErrorJson(MOD_ADS, ST_OK, ERR_NONE);
        SendErrorTLV(MOD_ADS, ST_OK, ERR_NONE);
    }

    return (int16_t)((rx[0] << 8) | rx[1]);
}

static uint8_t VoltageToPWM_0_255(float voltage)
{
    // Pastikan dalam range 0 .. ADC_INPUT_MAX_VOLT
    if (voltage < 0.0f)            voltage = 0.0f;
    if (voltage > ADC_INPUT_MAX_VOLT) voltage = ADC_INPUT_MAX_VOLT;

    // Mapping linier 0..ADC_INPUT_MAX_VOLT -> 0..255
    float scale = voltage / ADC_INPUT_MAX_VOLT;
    uint8_t pwm = (uint8_t)(scale * 255.0f + 0.5f);  // +0.5 untuk pembulatan

    return pwm;
}

static float ADS1115_ConvertRawToVolt(int16_t raw)
{
    float v = (float)raw * ADS_FS_VOLT / 32768.0f;

    // Clamp ke 0 .. ADC_INPUT_MAX_VOLT
    if (v < 0.0f)            v = 0.0f;
    if (v > ADC_INPUT_MAX_VOLT) v = ADC_INPUT_MAX_VOLT;

    return v;
}

static void ADS_Task(void)
{
    uint32_t now = HAL_GetTick();
    if (now - g_adsTick < ADS_READ_PERIOD_MS)
        return;

    g_adsTick = now;

    for (uint8_t ch = 0; ch < NUM_ANALOG; ch++)
    {
        g_anRaw[ch]   = ADS1115_ReadRaw(ch);
        float volt    = ADS1115_ConvertRawToVolt(g_anRaw[ch]);
        g_anCache[ch] = VoltageToPWM_0_255(volt);
    }
}

/* ==================== CRC16 MODBUS ==================== */
static uint16_t CRC16_Modbus(const uint8_t *data, uint16_t len)
{
    uint16_t crc = 0xFFFF;

    for (uint16_t i = 0; i < len; i++)
    {
        crc ^= data[i];
        for (uint8_t j = 0; j < 8; j++)
        {
            if (crc & 0x0001)
                crc = (crc >> 1) ^ 0xA001;
            else
                crc >>= 1;
        }
    }
    return crc;
}

/* ==================== TLV ENCODER (for UART) ==================== */
static size_t TLV_PutU8(uint8_t *buf, uint8_t tag, uint8_t val)
{
    buf[0] = tag;
    buf[1] = 1;
    buf[2] = val;
    return 3;
}

static size_t TLV_PutU16(uint8_t *buf, uint8_t tag, uint16_t val)
{
    buf[0] = tag;
    buf[1] = 2;
    buf[2] = (uint8_t)(val >> 8);
    buf[3] = (uint8_t)(val & 0xFF);
    return 4;
}

static size_t TLV_PutI16(uint8_t *buf, uint8_t tag, int16_t val)
{
    buf[0] = tag;
    buf[1] = 2;
    buf[2] = (uint8_t)((uint16_t)val >> 8);
    buf[3] = (uint8_t)((uint16_t)val & 0xFF);
    return 4;
}

static size_t TLV_PutU32(uint8_t *buf, uint8_t tag, uint32_t val)
{
    buf[0] = tag;
    buf[1] = 4;
    buf[2] = (uint8_t)(val >> 24);
    buf[3] = (uint8_t)(val >> 16);
    buf[4] = (uint8_t)(val >> 8);
    buf[5] = (uint8_t)(val & 0xFF);
    return 6;
}

static size_t TLV_PutU16Array4(uint8_t *buf, uint8_t tag, const uint16_t arr[4])
{
    buf[0] = tag;
    buf[1] = 8;
    for (int i = 0; i < 4; i++) {
        buf[2 + i*2]     = (uint8_t)(arr[i] >> 8);
        buf[2 + i*2 + 1] = (uint8_t)(arr[i] & 0xFF);
    }
    return 10;
}

static size_t TLV_EncodeMeasurement(const Measurement_t *m, uint8_t *out, size_t maxLen)
{
    if (maxLen < 48) return 0;

    size_t idx = 0;

    // Calculate timestamp epoch from RTC
    uint32_t timestamp = RTC_ToEpochSeconds(&m->rtc);

    idx += TLV_PutU32(&out[idx], TLV_TAG_SEQ, m->seq);
    idx += TLV_PutU32(&out[idx], TLV_TAG_TIMESTAMP, timestamp);
    idx += TLV_PutI16(&out[idx], TLV_TAG_TEMP, m->temp);
    idx += TLV_PutI16(&out[idx], TLV_TAG_HUM, m->hum);
    idx += TLV_PutU32(&out[idx], TLV_TAG_DIG_IN, m->dig_in);  // sekarang 4 byte (I1..I20), lihat catatan TLV_TAG_DIG_IN
    idx += TLV_PutU16Array4(&out[idx], TLV_TAG_AN_IN, m->an_in);
    idx += TLV_PutU8(&out[idx], TLV_TAG_Q, m->q);

    return idx;
}

static void SendErrorTLV(uint8_t mid, uint8_t st, uint8_t ec)
{
    uint8_t payload[16];
    size_t idx = 0;

    // mid -> TLV_TAG_ERR_MODULE
    payload[idx++] = TLV_TAG_ERR_MODULE;
    payload[idx++] = 1;
    payload[idx++] = mid;

    // st -> TLV_TAG_ERR_ACTIVE (pakai tag lama untuk "status")
    payload[idx++] = TLV_TAG_ERR_ACTIVE;
    payload[idx++] = 1;
    payload[idx++] = st;

    // ec -> TLV_TAG_ERR_CODE
    payload[idx++] = TLV_TAG_ERR_CODE;
    payload[idx++] = 1;
    payload[idx++] = ec;

    uint8_t frame[32];
    uint16_t fidx = 0;

    frame[fidx++] = TLV_SOF;
    frame[fidx++] = FRAME_TYPE_ERROR;
    frame[fidx++] = (idx >> 8) & 0xFF;
    frame[fidx++] = idx & 0xFF;

    memcpy(&frame[fidx], payload, idx);
    fidx += idx;

    uint16_t crc = CRC16_Modbus(frame, fidx);
    frame[fidx++] = (crc >> 8) & 0xFF;
    frame[fidx++] = crc & 0xFF;

    HAL_UART_Transmit(&huart2, frame, fidx, 100);
}

/* ----------------------------------------------------------------------
   SendReadyTLV()
   Dikirim SEKALI oleh STM32 ke ESP32 begitu STM32 benar2 masuk
   APP_STATE_RUN (SD mount + log recovery selesai, UART draining aktif,
   siap terima konfigurasi Rules). Ini bagian dari handshake sinkronisasi
   startup - ESP32 menunggu frame ini SEBELUM mengirim Rules, bukan lagi
   menebak pakai delay tetap. Payload kosong, keberadaan frame ini sendiri
   yg jadi sinyal. */
static void SendReadyTLV(void)
{
    uint8_t frame[8];
    uint16_t fidx = 0;

    frame[fidx++] = TLV_SOF;
    frame[fidx++] = FRAME_TYPE_READY;
    frame[fidx++] = 0; // len_h
    frame[fidx++] = 0; // len_l, payload kosong

    uint16_t crc = CRC16_Modbus(frame, fidx);
    frame[fidx++] = (crc >> 8) & 0xFF;
    frame[fidx++] = crc & 0xFF;

    HAL_UART_Transmit(&huart2, frame, fidx, 100);
    DBG_PRINT("[SYNC] READY dikirim ke ESP32\r\n");
}

/* ----------------------------------------------------------------------
   SendRulesAckTLV()
   Dikirim STM32 -> ESP32 SEGERA setelah ParseRulesTLV() selesai
   memproses & menerapkan Rules ke g_rules[]. Payload berisi jumlah rule
   yg berhasil di-parse, supaya ESP32 bisa memvalidasi jumlahnya cocok
   dgn yg dikirim (mendeteksi kalau ada TLV yg korup/rule yg gagal
   diparsing tanpa terlihat). Ini menutup requirement "STM32 mengirim
   ACK bahwa seluruh Rules telah diterapkan" & "validasi jumlah Rules
   yang diterima sesuai dgn yg dikirim". */
static void SendRulesAckTLV(uint8_t ruleCount)
{
    uint8_t payload[4];
    size_t idx = 0;

    payload[idx++] = TAG_RULE_COUNT;
    payload[idx++] = 1;
    payload[idx++] = ruleCount;

    uint8_t frame[16];
    uint16_t fidx = 0;

    frame[fidx++] = TLV_SOF;
    frame[fidx++] = FRAME_TYPE_RULES_ACK;
    frame[fidx++] = (idx >> 8) & 0xFF;
    frame[fidx++] = idx & 0xFF;

    memcpy(&frame[fidx], payload, idx);
    fidx += idx;

    uint16_t crc = CRC16_Modbus(frame, fidx);
    frame[fidx++] = (crc >> 8) & 0xFF;
    frame[fidx++] = crc & 0xFF;

    HAL_UART_Transmit(&huart2, frame, fidx, 100);

    DBG_PRINTF(
             "[SYNC] RULES_ACK dikirim, count=%u\r\n", ruleCount);
}

static bool SendMeasurementTLV(const Measurement_t *m)
{
    uint8_t tlvPayload[64];
    size_t tlvLen = TLV_EncodeMeasurement(m, tlvPayload, sizeof(tlvPayload));
    if (tlvLen == 0) {
        DBG_PRINT("[TX] TLV encode failed\r\n");
        return false;
    }

    uint8_t frame[UART_FRAME_MAX_LEN];
    uint16_t idx = 0;

    frame[idx++] = TLV_SOF;
    frame[idx++] = FRAME_TYPE_DATA;
    frame[idx++] = (tlvLen >> 8) & 0xFF;
    frame[idx++] = tlvLen & 0xFF;

    memcpy(&frame[idx], tlvPayload, tlvLen);
    idx += tlvLen;

    uint16_t crc = CRC16_Modbus(frame, idx);
    frame[idx++] = (crc >> 8) & 0xFF;
    frame[idx++] = crc & 0xFF;

    if (HAL_UART_Transmit(&huart2, frame, idx, 200) != HAL_OK) {
        DBG_PRINT("[TX] UART transmit failed\r\n");
        return false;
    }

    DBG_PRINTF(
             "[TX] Sent TLV seq=%lu len=%u\r\n",
             (unsigned long)m->seq, (unsigned)tlvLen);

    return true;
}

/* ==================== TLV PARSER (from ESP32) ==================== */
static uint32_t TLV_ReadU32BE(const uint8_t *p)
{
    return ((uint32_t)p[0] << 24) |
           ((uint32_t)p[1] << 16) |
           ((uint32_t)p[2] << 8)  |
           p[3];
}

/* ==================== JSON ENCODER (for SD & Debug) ==================== */
static size_t JSON_EncodeMeasurement(const Measurement_t *m, char *out, size_t maxLen)
{
    char ts[32];
    char digArr[64];
    char anArr[32];
    char qArr[24];
    char *p;
    int n;

    // 1) Build timestamp string "YYYY-MM-DDTHH:MM:SSZ"
    snprintf(ts, sizeof(ts), "%04u-%02u-%02uT%02u:%02u:%02uZ",
             m->rtc.year, m->rtc.month, m->rtc.day,
             m->rtc.hours, m->rtc.minutes, m->rtc.seconds);

    // 2) Build dig_in array string [1,0,1,0,...]
    // Jumlah elemen mengikuti Addon Type aktif (11 utk None/GSM, 19 utk
    // Expansion Input), identik dgn perilaku buildDigArray() di ESP32.
    uint8_t digCount = Addon_ActiveInputCount();
    p = digArr;
    *p++ = '[';
    for (uint8_t i = 0; i < digCount; i++) {
        uint8_t bit = (m->dig_in & (1U << i)) ? 1 : 0;
        n = snprintf(p, sizeof(digArr) - (p - digArr), "%u%s",
                     bit, (i < digCount - 1) ? "," : "");
        if (n > 0) p += n;
    }
    *p++ = ']';
    *p = '\0';

    // 3) Build an_in array string [255,255,255,255]
    snprintf(anArr, sizeof(anArr), "[%u,%u,%u,%u]",
             m->an_in[0], m->an_in[1], m->an_in[2], m->an_in[3]);

    // 4) Build q array string [0,1,0,1]
    p = qArr;
    *p++ = '[';
    for (uint8_t i = 0; i < NUM_OUTPUTS; i++) {
        uint8_t bit = (m->q & (1U << i)) ? 1 : 0;
        n = snprintf(p, sizeof(qArr) - (p - qArr), "%u%s",
                     bit, (i < NUM_OUTPUTS - 1) ? "," : "");
        if (n > 0) p += n;
    }
    *p++ = ']';
    *p = '\0';

    // 5) Build complete JSON
    int len = snprintf(out, maxLen,
        "{\"timestamp\":\"%s\","
        "\"env\":{\"temp\":%.1f,\"hum\":%.1f},"
        "\"dig_in\":%s,"
        "\"an_in\":%s,"
        "\"q\":%s,"
        "\"seq\":%lu}\n",
        ts,
        m->temp / 10.0f,
        m->hum / 10.0f,
        digArr,
        anArr,
        qArr,
        (unsigned long)m->seq
    );

    if (len < 0 || (size_t)len >= maxLen) return 0;
    return (size_t)len;
}

static bool JSON_ParseSeqFromLine(const char *line, uint32_t *outSeq)
{
    const char *p = strstr(line, "\"seq\":");
    if (!p) return false;

    p += 6;
    *outSeq = (uint32_t)strtoul(p, NULL, 10);
    return (*outSeq > 0);
}

/* ==================== UART CALLBACKS ==================== */
void HAL_UART_RxCpltCallback(UART_HandleTypeDef *huart)
{
    if (huart == &huart2)
    {
        uint8_t b = g_rxByte;

        if (g_frameIdx == 0)
        {
            if (b == TLV_SOF)
            {
                g_frameBuf[0] = b;
                g_frameIdx    = 1;
                g_expectedLen = -1;
            }
        }
        else
        {
            if (g_frameIdx < RX_BUF_SIZE)
            {
                g_frameBuf[g_frameIdx++] = b;
            }
            else
            {
                g_frameIdx    = 0;
                g_expectedLen = -1;
            }

            // After SOF + TYPE + LEN_H + LEN_L (4 bytes)
            if (g_frameIdx == 4)
            {
                uint16_t payloadLen = ((uint16_t)g_frameBuf[2] << 8) | g_frameBuf[3];
                if (payloadLen > RULE_MAX_PAYLOAD)
                {
                    g_frameIdx    = 0;
                    g_expectedLen = -1;
                }
                else
                {
                    g_expectedLen = 4 + payloadLen + 2;
                }
            }

            if (g_expectedLen > 0 && g_frameIdx == g_expectedLen)
            {
                uint16_t payloadLen = ((uint16_t)g_frameBuf[2] << 8) | g_frameBuf[3];

                uint16_t crcRecv = ((uint16_t)g_frameBuf[g_frameIdx-2] << 8) |
                                    g_frameBuf[g_frameIdx-1];
                uint16_t crcCalc = CRC16_Modbus(g_frameBuf, g_frameIdx-2);

                if (crcRecv == crcCalc)
                {
                    uint8_t frameType = g_frameBuf[1];
                    if (g_deferredCount < DEFERRED_FRAME_SLOTS) {
                        memcpy((void*)g_deferredFrames[g_deferredTail].buf, &g_frameBuf[4], payloadLen);
                        g_deferredFrames[g_deferredTail].len  = payloadLen;
                        g_deferredFrames[g_deferredTail].type = frameType;
                        g_deferredTail = (g_deferredTail + 1) % DEFERRED_FRAME_SLOTS;
                        g_deferredCount++;
                    } else {
                        /* Ring buffer penuh (main loop belum sempat drain -
                           harusnya sangat jarang dgn 4 slot). Dibuang dgn
                           jejak counter, BUKAN diam2 tanpa indikasi sama
                           sekali seperti implementasi lama. */
                        g_deferredDroppedCount++;
                    }
                }

                g_frameIdx    = 0;
                g_expectedLen = -1;
            }
        }

        HAL_UART_Receive_IT(&huart2, &g_rxByte, 1);
    }

    if (huart == &huart1)
    {
        uint8_t b = g_rs485RxByte;

        if (g_rs485Idx < sizeof(g_rs485Buf) - 1)
        {
            g_rs485Buf[g_rs485Idx++] = b;
        }

        if (b == '\n')
        {
            g_rs485Buf[g_rs485Idx] = '\0';
            g_rs485Idx = 0;
        }

        HAL_UART_Receive_IT(&huart1, &g_rs485RxByte, 1);
    }
}

/* ==================== RULES ==================== */
static void Rules_Reset(void)
{
    for (int q = 0; q < NUM_OUTPUTS; q++)
    {
        g_rules[q].logic      = RULE_LOGIC_OFF;
        g_rules[q].inputCount = 0;
        memset(g_rules[q].inputs, 0, sizeof(g_rules[q].inputs));
    }
}

static void ParseOneRuleString(const char *ruleStr)
{
    if (ruleStr == NULL || ruleStr[0] != 'Q') return;

    int qNum = atoi(&ruleStr[1]);
    if (qNum < 1 || qNum > (int)NUM_OUTPUTS) return;
    int qIdx = qNum - 1;

    const char *p = strchr(ruleStr, ':');
    if (!p) return;
    p++;

    const char *p2 = strchr(p, ':');
    if (!p2) return;

    char logicStr[8] = {0};
    size_t logicLen = (size_t)(p2 - p);
    if (logicLen >= sizeof(logicStr))
        logicLen = sizeof(logicStr) - 1;
    memcpy(logicStr, p, logicLen);
    logicStr[logicLen] = '\0';

    RuleLogic_t logic = RULE_LOGIC_OFF;
    if      (strcmp(logicStr, "OR")  == 0) logic = RULE_LOGIC_OR;
    else if (strcmp(logicStr, "AND") == 0) logic = RULE_LOGIC_AND;
    else if (strcmp(logicStr, "NOT") == 0) logic = RULE_LOGIC_NOT;

    g_rules[qIdx].logic      = logic;
    g_rules[qIdx].inputCount = 0;

    const char *r = p2 + 1;
    while (*r != '\0')
    {
        if (*r == 'I')
        {
            int inNum = atoi(r + 1);
            /* I1..I11 = native GPIO, I12 = reserved (belum ada GPIO fisik),
             * I13..I20 = addon PCF8574 (lihat NUM_INPUTS_TOTAL) */
            if (inNum >= 1 && inNum <= (int)NUM_INPUTS_TOTAL)
            {
                if (g_rules[qIdx].inputCount < NUM_INPUTS_TOTAL)
                {
                    g_rules[qIdx].inputs[g_rules[qIdx].inputCount++] = (uint8_t)inNum;
                }
            }
            while (*r && *r != ',' && *r != '\0') r++;
        }
        else
        {
            r++;
        }
    }
}

static void ParseRulesTLV(const uint8_t *tlv, size_t len)
{
    Rules_Reset();

    size_t i = 0;
    uint8_t parsedCount = 0;
    while (i + 2 <= len) {
        uint8_t tag = tlv[i];
        uint8_t l   = tlv[i + 1];

        if (i + 2 + l > len) break;

        if (tag == TAG_RULE) {
            char ruleStr[RULE_STR_MAX_LEN];
            size_t copyLen = (l < RULE_STR_MAX_LEN - 1) ? l : (RULE_STR_MAX_LEN - 1);
            memcpy(ruleStr, &tlv[i + 2], copyLen);
            ruleStr[copyLen] = '\0';
            ParseOneRuleString(ruleStr);
            parsedCount++;
        }

        i += 2 + l;
    }

    g_ruleUpdated = 1;

    /* Beri tahu ESP32 bahwa Rules sudah diterapkan + berapa jumlah yg
       berhasil diparsing, supaya ESP32 bisa validasi & retry kalau perlu
       (lihat penjelasan lengkap di SendRulesAckTLV()). */
    SendRulesAckTLV(parsedCount);
}

static void ParseRTCTLV(const uint8_t *tlv, size_t len)
{
    size_t i = 0;
    while (i + 2 <= len) {
        uint8_t tag = tlv[i];
        uint8_t l   = tlv[i + 1];

        if (i + 2 + l > len) break;

        if (tag == TAG_RTC_TS && l == 4) {
            uint32_t epoch = TLV_ReadU32BE(&tlv[i + 2]);
            DS3231_TimeTypeDef t;
            EpochToRTC(epoch, &t);

            if (DS3231_SetTime(&t)) {
                DBG_PRINT("[RTC] Set from ESP32 OK\r\n");
            } else {
                DBG_PRINT("[RTC] Set FAILED\r\n");
            }
        }

        i += 2 + l;
    }
}

static void ParseACKTLV(const uint8_t *tlv, size_t len)
{
    size_t i = 0;
    while (i + 2 <= len) {
        uint8_t tag = tlv[i];
        uint8_t l   = tlv[i + 1];

        if (i + 2 + l > len) break;

        if (tag == TLV_TAG_SEQ && l == 4) {
            g_ack_seq = TLV_ReadU32BE(&tlv[i + 2]);
            g_ack_pending = 1;

            DBG_PRINTF(
                     "[ACK] Received seq=%lu\r\n", (unsigned long)g_ack_seq);
        }

        i += 2 + l;
    }
}

static void RecomputeCombinedInputMask(void)
{
    uint32_t combined = (uint32_t)g_nativeInputMask |
                         ((uint32_t)g_addonInputMask << ADDON_INPUT_BIT_OFFSET);

    if (combined != g_inputMaskStable)
    {
        g_inputMaskStable = combined;
        g_io_changed_flag = 1;
    }
}

/* Jumlah Digital Input yang aktif saat ini, mengikuti Addon Type:
 *   - Expansion Input -> NUM_INPUTS_TOTAL (19)
 *   - None / GSM      -> NUM_INPUTS (11)
 * Dipakai oleh semua jalur yang membentuk array dig_in (log JSON ke SD
 * Card & debug JSON) supaya jumlahnya identik dengan firmware ESP32. */
static inline uint8_t Addon_ActiveInputCount(void)
{
    return g_addonExpansionActive ? (uint8_t)NUM_INPUTS_TOTAL : (uint8_t)NUM_INPUTS;
}

static void ParseAddonTLV(const uint8_t *tlv, size_t len)
{
    size_t i = 0;
    while (i + 2 <= len)
    {
        uint8_t tag = tlv[i];
        uint8_t l   = tlv[i + 1];

        if (i + 2 + l > len) break;

        if (tag == TAG_ADDON_MASK && l == 1)
        {
            uint8_t newAddonMask = tlv[i + 2];

            /* Frame FRAME_TYPE_ADDON hanya pernah dikirim ESP32 ketika
             * Addon Type = Expansion Input, jadi kedatangannya (terlepas
             * dari mask-nya berubah atau tidak) menandai Addon Type aktif. */
            if (!g_addonExpansionActive)
            {
                g_addonExpansionActive = 1;
                DBG_PRINTF(
                         "[ADDON] Expansion Input terdeteksi aktif, Digital Input = %u channel\r\n",
                         (unsigned)NUM_INPUTS_TOTAL);
            }

            if (newAddonMask != g_addonInputMask)
            {
                g_addonInputMask = newAddonMask;
                RecomputeCombinedInputMask();

                DBG_PRINTF(
                         "[ADDON] mask updated from ESP32: 0x%02X\r\n",
                         newAddonMask);
            }
        }

        i += 2 + l;
    }
}

static uint8_t EvalOutputState(int qIdx, uint32_t inputMask)
{
    RuleDef_t *r = &g_rules[qIdx];

    if (r->logic == RULE_LOGIC_OFF || r->inputCount == 0)
        return 0;

    if (r->logic == RULE_LOGIC_NOT)
    {
        uint8_t in = r->inputs[0];
        uint8_t state = (inputMask & (1U << (in - 1))) ? 1 : 0;
        return !state;
    }

    if (r->logic == RULE_LOGIC_OR)
    {
        for (uint8_t i = 0; i < r->inputCount; i++)
        {
            uint8_t in = r->inputs[i];
            if (inputMask & (1U << (in - 1)))
                return 1;
        }
        return 0;
    }

    if (r->logic == RULE_LOGIC_AND)
    {
        for (uint8_t i = 0; i < r->inputCount; i++)
        {
            uint8_t in = r->inputs[i];
            if (!(inputMask & (1U << (in - 1))))
                return 0;
        }
        return 1;
    }

    return 0;
}

static void ApplyRules(uint32_t inputMask)
{
    for (int q = 0; q < NUM_OUTPUTS; q++)
    {
        uint8_t on = EvalOutputState(q, inputMask);
        HAL_GPIO_WritePin(g_outputs[q].Port, g_outputs[q].Pin,
                          on ? GPIO_PIN_SET : GPIO_PIN_RESET);
    }
}

static void PrintRuleStatus(void)
{
    /* Fungsi ini murni debug/monitoring (dump status rule ke UART1),
     * bukan bagian protokol - seluruh isi di-strip saat DEBUG_ENABLE=0
     * supaya loop & snprintf increment di bawah juga tidak jalan sia-sia. */
#if DEBUG_ENABLE
    DBG_PRINT("[RULE] Current configuration:\r\n");

    for (int q = 0; q < NUM_OUTPUTS; q++)
    {
        RuleDef_t *r = &g_rules[q];

        const char *logicName = "OFF";
        if      (r->logic == RULE_LOGIC_OR)  logicName = "OR";
        else if (r->logic == RULE_LOGIC_AND) logicName = "AND";
        else if (r->logic == RULE_LOGIC_NOT) logicName = "NOT";

        int len = snprintf(g_debugBuf, sizeof(g_debugBuf),
                           "  Q%d: %s (", q + 1, logicName);

        for (uint8_t i = 0; i < r->inputCount; i++)
        {
            len += snprintf(g_debugBuf + len, sizeof(g_debugBuf) - len,
                            "I%u%s", r->inputs[i],
                            (i == r->inputCount - 1) ? "" : ",");
        }
        snprintf(g_debugBuf + len, sizeof(g_debugBuf) - len, ")\r\n");
        UART_Print(g_debugBuf);
    }
#endif
}

static void OnFrameReceived(uint8_t *payload, uint16_t len, uint8_t frameType)
{
    DBG_PRINTF(
             "[RX] Frame type=0x%02X len=%u\r\n", frameType, len);

    switch (frameType) {
        case FRAME_TYPE_RULES:
//            Debug_DumpTLV("[RX][RULES]", payload, len);
            ParseRulesTLV(payload, len);
            break;

        case FRAME_TYPE_RTC:
//            Debug_DumpTLV("[RX][RTC]", payload, len);
            ParseRTCTLV(payload, len);
            break;

        case FRAME_TYPE_ACK:
//            Debug_DumpTLV("[RX][ACK]", payload, len);
            ParseACKTLV(payload, len);
            break;

        case FRAME_TYPE_ADDON:
//            Debug_DumpTLV("[RX][ADDON]", payload, len);
            ParseAddonTLV(payload, len);
            break;

        default:
            DBG_PRINT("[RX] Unknown frame type\r\n");
            break;
    }
}

/* ==================== SD CARD & LOG (JSON format) ==================== */
static void Log_InitRuntime(void)
{
    g_sd_mounted = 0;
    g_nextSeq    = 1;
}

static bool SD_MountTask(void)
{
    static uint32_t lastTryMs   = 0;
    static FRESULT  lastFr      = FR_OK;

    if (g_sd_mounted) return true;

    uint32_t now = HAL_GetTick();
    if ((now - lastTryMs) < 1000U) {   // coba tiap 1 detik
        return false;
    }
    lastTryMs = now;

    // Paksa init ulang disk (akan memanggil SD_disk_initialize)
    disk_initialize(0);

    FRESULT fr = f_mount(&USERFatFS, (TCHAR const*)USERPath, 1);
    if (fr == FR_OK) {
        g_sd_mounted = 1;
        lastFr       = fr;

        if (g_err_sd) {
            g_err_sd = 0;
            Debug_ErrorJson(MOD_SD, ST_OK, ERR_NONE);
            SendErrorTLV(MOD_SD, ST_OK, ERR_NONE);
        }
        DBG_PRINT("[SD] Mounted OK\r\n");
        Emergency_FlushToSD();
        return true;
    } else {
        if (!g_err_sd) {
            g_err_sd = 1;
            Debug_ErrorJson(MOD_SD, ST_ERR, ERR_NOT_FOUND);  // kartu / filesystem tidak ditemukan
            SendErrorTLV(MOD_SD, ST_ERR, ERR_NOT_FOUND);
        }

        // Hanya print kalau kode error berubah
        if (fr != lastFr) {
            lastFr = fr;
            DBG_PRINTF(
                     "[SD] Mount ERR=%d\r\n", fr);
        }
    }
    return false;
}

/* ----------------------------------------------------------------------
   Seq_LoadPersisted() / Seq_Persist()

   Counter sequence number DISIMPAN TERPISAH dari isi queue (seq.dat),
   bukan diturunkan semata-mata dari baris yang masih pending di
   log.json. Alasan: begitu semua event ter-ACK dan log.json kosong
   (kondisi NORMAL saat koneksi cloud lancar), scan log.json akan
   selalu menghasilkan maxSeq=0 -> next=1, sehingga nomor urut kembali
   dari awal padahal cloud sudah punya histori jauh di depan. seq.dat
   menjamin monotonic counter tetap benar walau queue kosong;
   log.json tetap dipakai sbg cross-check kedua (fallback) kalau
   seq.dat hilang/corrupt/kartu SD diganti.
   ---------------------------------------------------------------------- */
static bool Seq_LoadPersisted(uint32_t *outSeq)
{
    FIL f;
    if (f_open(&f, SEQ_FILE_NAME, FA_READ | FA_OPEN_EXISTING) != FR_OK) {
        return false;
    }

    char buf[16] = {0};
    UINT br = 0;
    FRESULT fr = f_read(&f, buf, sizeof(buf) - 1, &br);
    f_close(&f);

    if (fr != FR_OK || br == 0) {
        return false;
    }

    buf[br] = '\0';
    uint32_t val = (uint32_t)strtoul(buf, NULL, 10);
    if (val == 0) {
        return false; /* file kosong/corrupt dianggap tidak valid */
    }

    *outSeq = val;
    return true;
}

static bool Seq_Persist(uint32_t nextSeq)
{
    FIL f;
    FRESULT fr = f_open(&f, SEQ_FILE_NAME, FA_WRITE | FA_CREATE_ALWAYS);
    if (fr != FR_OK) {
        DBG_PRINT("[SEQ] persist open failed\r\n");
        return false;
    }

    char buf[16];
    int len = snprintf(buf, sizeof(buf), "%lu", (unsigned long)nextSeq);
    UINT bw = 0;
    fr = f_write(&f, buf, (UINT)len, &bw);
    f_sync(&f);
    f_close(&f);

    if (fr != FR_OK || (int)bw != len) {
        DBG_PRINT("[SEQ] persist write failed\r\n");
        return false;
    }
    return true;
}

/* ----------------------------------------------------------------------
   Log_QuarantineBadLines()

   Baris di log.json yang gagal di-parse (mis. akibat torn write saat
   power loss persis di tengah f_write) SEBELUMNYA hanya di-skip diam2
   oleh Log_GetFirstPendingMeasurement()/Log_RemoveSeq() - baris itu
   tidak pernah terkirim, tidak pernah dihapus, dan event di dalamnya
   HILANG PERMANEN tanpa ada peringatan ke operator.

   Fungsi ini dipanggil sekali saat recovery: baris valid ditulis balik
   ke log.json, baris yang gagal parse dipindah ke log_bad.json supaya
   masih bisa diaudit manual, dan error dilaporkan ke ESP32/UART supaya
   kejadian ini TIDAK diam-diam.
   ---------------------------------------------------------------------- */
static void Log_QuarantineBadLines(void)
{
    FIL src, dstGood, dstBad;
    if (f_open(&src, LOG_FILE_NAME, FA_READ | FA_OPEN_EXISTING) != FR_OK) {
        return;
    }
    if (f_open(&dstGood, "log_tmp.json", FA_WRITE | FA_CREATE_ALWAYS) != FR_OK) {
        f_close(&src);
        return;
    }
    if (f_open(&dstBad, LOG_BAD_FILE_NAME, FA_WRITE | FA_OPEN_APPEND) != FR_OK) {
        f_close(&src);
        f_close(&dstGood);
        return;
    }

    char line[JSON_LINE_MAX];
    uint32_t seq;
    uint32_t badCount = 0;
    UINT bw;

    while (f_gets(line, sizeof(line), &src) != NULL) {
        HAL_IWDG_Refresh(&hiwdg);
        size_t len = strlen(line);
        if (JSON_ParseSeqFromLine(line, &seq)) {
            f_write(&dstGood, line, len, &bw);
        } else if (len > 1) {
            /* line > 1 char supaya baris kosong/newline sisa tidak dianggap "bad" */
            f_write(&dstBad, line, len, &bw);
            badCount++;
        }
    }

    f_sync(&dstGood);
    f_sync(&dstBad);
    f_close(&src);
    f_close(&dstGood);
    f_close(&dstBad);

    if (badCount > 0) {
        DBG_PRINTF(
                 "[LOG] %lu baris korup dikarantina ke %s\r\n",
                 (unsigned long)badCount, LOG_BAD_FILE_NAME);
        SendErrorTLV(MOD_SD, ST_ERR, ERR_CRC);
    }

    /* Ganti log.json dengan versi bersih (hasil rewrite) */
    f_unlink(LOG_FILE_NAME);
    f_rename("log_tmp.json", LOG_FILE_NAME);
}

/* ----------------------------------------------------------------------
   Emergency_Push() / Emergency_FlushToSD()

   Fallback TERAKHIR: kejadian ini hanya bisa muncul saat SD TIDAK
   ter-mount (kartu lepas/rusak) DAN TX_Process sedang sibuk mengurus
   event lain (retry) di saat yang sama. Sebelumnya kombinasi ini
   membuat event baru terbuang total tanpa jejak di manapun (lihat
   TX_StartNew: kalau state != IDLE, event ditolak; kalau SD juga tidak
   mounted, tidak ada log.json untuk menampungnya). Buffer RAM kecil ini
   menahan event tsb sementara, dan begitu SD kembali ter-mount akan
   di-flush jadi baris log.json biasa (lewat jalur normal, ikut serta
   dalam scan Seq/queue seperti event lainnya).

   CATATAN: ini RAM, jadi tetap hilang kalau restart terjadi SEBELUM SD
   kembali. Bukan pengganti SD - hanya menutup celah kecil, bukan
   solusi utama. Kalau buffer penuh (SD mati berkepanjangan), event
   terlama sengaja di-drop dengan log eksplisit (bukan diam2), supaya
   operator sadar kartu SD perlu segera ditangani.
   ---------------------------------------------------------------------- */
static void Emergency_Push(const Measurement_t *m)
{
    if (g_emergencyCount >= EMERGENCY_BUF_SLOTS) {
        DBG_PRINTF(
                 "[EMERGENCY] buffer penuh, seq=%lu DIBUANG (SD mati terlalu lama!)\r\n",
                 (unsigned long)m->seq);
        return;
    }
    g_emergencyBuf[g_emergencyCount++] = *m;
    DBG_PRINTF(
             "[EMERGENCY] seq=%lu ditahan di RAM (SD tidak mounted, TX busy) [%u/%u]\r\n",
             (unsigned long)m->seq, g_emergencyCount, EMERGENCY_BUF_SLOTS);
}

static void Emergency_FlushToSD(void)
{
    if (g_emergencyCount == 0 || !g_sd_mounted) return;

    for (uint8_t i = 0; i < g_emergencyCount; i++) {
        char jsonLine[JSON_LINE_MAX];
        size_t jsonLen = JSON_EncodeMeasurement(&g_emergencyBuf[i], jsonLine, sizeof(jsonLine));
        if (jsonLen > 0 && Log_AppendJSON(jsonLine)) {
            g_pendingLogCount++;
        } else {
            DBG_PRINT("[EMERGENCY] flush ke log.json gagal, data tetap di RAM\r\n");
            return; /* jangan hapus dari buffer kalau gagal tulis */
        }
    }

    DBG_PRINTF(
             "[EMERGENCY] %u event berhasil di-flush ke log.json\r\n", g_emergencyCount);
    g_emergencyCount = 0;
}

static bool Log_RecoverTask(void)
{
    static uint8_t done = 0;
    if (done) return true;
    if (!g_sd_mounted) return false;

    FIL file;
    FRESULT fr;

    // Pastikan log.json ada
    fr = f_open(&file, LOG_FILE_NAME, FA_READ | FA_OPEN_EXISTING);
    if (fr != FR_OK) {
        // Buat file kosong
        fr = f_open(&file, LOG_FILE_NAME, FA_WRITE | FA_CREATE_ALWAYS);
        if (fr != FR_OK) {
            DBG_PRINT("[LOG] create log.json failed\r\n");
            return false;
        }
        f_close(&file);
    } else {
        f_close(&file);
        // Karantina dulu baris yang gagal parse (torn write dsb), supaya
        // event korup tidak diam2 hilang & tidak ikut mengacaukan scan seq.
        Log_QuarantineBadLines();
    }

    // Scan log.json (yg sudah bersih, atau memang baru dibuat kosong)
    // untuk mencari seq maksimum yang masih pending.
    char line[JSON_LINE_MAX];
    uint32_t seq;
    uint32_t maxSeq = 0;
    uint32_t lineCount = 0;

    fr = f_open(&file, LOG_FILE_NAME, FA_READ | FA_OPEN_EXISTING);
    if (fr == FR_OK) {
        while (f_gets(line, sizeof(line), &file) != NULL) {
            HAL_IWDG_Refresh(&hiwdg);
            if (JSON_ParseSeqFromLine(line, &seq)) {
                if (seq > maxSeq) maxSeq = seq;
                lineCount++;
            }
        }
        f_close(&file);
    }
    g_pendingLogCount = lineCount;

    /* ---- Sumber kebenaran GANDA untuk next-seq ----
       1) seq.dat  : counter persisten independen dari isi queue. Ini
                     yg menjamin monotonic tetap benar walau log.json
                     KOSONG (semua event sudah ter-ACK - kondisi
                     NORMAL, bukan edge case langka).
       2) log.json : fallback kalau seq.dat hilang/corrupt/kartu SD
                     baru/diganti. Juga jaring pengaman kalau seq.dat
                     sempat ketinggalan (mis. crash tepat sebelum
                     Seq_Persist tapi sesudah Log_AppendJSON).
       next-seq final = MAX dari kedua sumber - tidak pernah mundur. */
    uint32_t fromCounterFile = 0;
    bool haveCounterFile = Seq_LoadPersisted(&fromCounterFile);
    uint32_t fromLog = (maxSeq == 0) ? 0 : (maxSeq + 1);

    uint32_t resolved = haveCounterFile ? fromCounterFile : 0;
    if (fromLog > resolved) resolved = fromLog;
    if (resolved == 0) resolved = 1;

    g_nextSeq = resolved;

    /* Selalu tulis ulang seq.dat dgn nilai yg sudah diresolusi, supaya
       file ini konsisten lagi kalau tadi hilang/corrupt/ketinggalan. */
    Seq_Persist(g_nextSeq);

    DBG_PRINTF(
             "[LOG] Recovery done, nextSeq=%lu (counter_file=%s val=%lu, log_max+1=%lu), pending=%lu\r\n",
             (unsigned long)g_nextSeq,
             haveCounterFile ? "OK" : "MISSING",
             (unsigned long)fromCounterFile,
             (unsigned long)fromLog,
             (unsigned long)g_pendingLogCount);

    done = 1;
    return true;
}

static bool Log_AppendJSON(const char *jsonLine)
{
    FIL f;
    FRESULT fr = f_open(&f, LOG_FILE_NAME, FA_WRITE | FA_OPEN_APPEND);
    if (fr != FR_OK) {
        DBG_PRINT("[LOG] Open failed\r\n");
        if (!g_err_sd) {
            g_err_sd = 1;
            Debug_ErrorJson(MOD_SD, ST_ERR, ERR_NOT_FOUND);
            SendErrorTLV(MOD_SD, ST_ERR, ERR_NOT_FOUND);
        }
        f_close(&f);  // jaga-jaga
        f_mount(NULL, (TCHAR const*)USERPath, 0); // unmount
        g_sd_mounted = 0;
        return false;
    }

    UINT bw;
    size_t len = strlen(jsonLine);
    fr = f_write(&f, jsonLine, len, &bw);
    f_sync(&f);
    f_close(&f);

    if (fr != FR_OK || bw != len) {
        DBG_PRINT("[LOG] Write failed\r\n");
        if (!g_err_sd) {
            g_err_sd = 1;
            Debug_ErrorJson(MOD_SD, ST_ERR, ERR_CRC);   // treat as data error
            SendErrorTLV(MOD_SD, ST_ERR, ERR_CRC);
        }
        f_close(&f);
        f_mount(NULL, (TCHAR const*)USERPath, 0);
        g_sd_mounted = 0;
        return false;
    }

    if (g_err_sd) {
        g_err_sd = 0;
        Debug_ErrorJson(MOD_SD, ST_OK, ERR_NONE);
        SendErrorTLV(MOD_SD, ST_OK, ERR_NONE);
    }

    return true;
}

static bool Log_RemoveSeq(uint32_t seqToRemove)
{
    FIL f;
    FRESULT fr = f_open(&f, LOG_FILE_NAME, FA_READ | FA_WRITE);
    if (fr != FR_OK) {
        DBG_PRINT("[LOG] Open for remove failed\r\n");
        f_mount(NULL, (TCHAR const*)USERPath, 0);
        g_sd_mounted = 0;
        return false;
    }

    char line[JSON_LINE_MAX];
    uint32_t seq;
    UINT bw;
    DWORD readPos  = 0;
    DWORD writePos = 0;
    bool removed   = false;

    while (1) {
        HAL_IWDG_Refresh(&hiwdg);
        // Posisikan ke offset baca
        fr = f_lseek(&f, readPos);
        if (fr != FR_OK) break;

        // Baca satu baris
        if (f_gets(line, sizeof(line), &f) == NULL) {
            // EOF
            break;
        }

        // Update posisi baca ke setelah baris ini
        readPos = f_tell(&f);

        // Ambil seq
        if (JSON_ParseSeqFromLine(line, &seq) && seq == seqToRemove) {
            // Skip baris ini (tidak ditulis kembali)
            removed = true;
            continue;
        }

        // Tulis ke posisi writePos
        fr = f_lseek(&f, writePos);
        if (fr != FR_OK) break;

        size_t len = strlen(line);
        fr = f_write(&f, line, len, &bw);
        if (fr != FR_OK || bw != len) {
            DBG_PRINT("[LOG] write during remove failed\r\n");
            break;
        }

        writePos += bw;
    }

    // Jika ada baris dihapus, truncate file ke writePos
    if (removed) {
        fr = f_lseek(&f, writePos);
        if (fr == FR_OK) {
            f_truncate(&f);   // truncate di posisi writePos
        }
        if (g_pendingLogCount > 0) g_pendingLogCount--;
        if (seqToRemove == g_lastFailedSeq) {
            g_lastFailedSeq = 0;
        }
    }

    f_sync(&f);
    f_close(&f);

    return removed;
}

static void SD_StatusTask(uint32_t now)
{
    static uint32_t lastCheckMs = 0;

    // Jalan tiap SD_STATUS_INTERVAL_MS (default 3000 ms)
    if ((now - lastCheckMs) < SD_STATUS_INTERVAL_MS) {
        return;
    }
    lastCheckMs = now;

    // Kalau SD belum ter-mount, coba mount
    if (!g_sd_mounted) {
        SD_MountTask();
        return;
    }

    // Ambil waktu sekarang dari RTC
    DS3231_TimeTypeDef rtc;
    if (!DS3231_ReadTime(&rtc)) {
        // Kalau RTC gagal dibaca, tidak update status.json
        return;
    }

    // Bentuk string timestamp ISO: "YYYY-MM-DDTHH:MM:SSZ"
    char ts[32];
    snprintf(ts, sizeof(ts), "%04u-%02u-%02uT%02u:%02u:%02uZ",
             rtc.year, rtc.month, rtc.day,
             rtc.hours, rtc.minutes, rtc.seconds);

    // JSON 1 baris, berisi waktu terakhir online
    // Contoh: {"last_online":"2025-01-08T12:34:56Z"}
    char jsonLine[96];
    int len = snprintf(jsonLine, sizeof(jsonLine),
                       "{\"last_online\":\"%s\"}\r\n", ts);
    if (len <= 0 || len >= (int)sizeof(jsonLine)) {
        return;
    }

    FIL f;
    FRESULT fr = f_open(&f, STATUS_FILE_NAME, FA_WRITE | FA_CREATE_ALWAYS);
    if (fr != FR_OK) {
        DBG_PRINT("[STATUS] Open status.json failed\r\n");
        if (!g_err_sd) {
            g_err_sd = 1;
            Debug_ErrorJson(MOD_SD, ST_ERR, ERR_NOT_FOUND);
            SendErrorTLV(MOD_SD, ST_ERR, ERR_NOT_FOUND);
        }
        // Unmount supaya nanti dicoba mount ulang
        f_mount(NULL, (TCHAR const*)USERPath, 0);
        g_sd_mounted = 0;
        return;
    }

    UINT bw;
    fr = f_write(&f, jsonLine, len, &bw);
    f_sync(&f);
    f_close(&f);

    if (fr != FR_OK || bw != (UINT)len) {
        DBG_PRINT("[STATUS] Write status.json failed\r\n");
        if (!g_err_sd) {
            g_err_sd = 1;
            Debug_ErrorJson(MOD_SD, ST_ERR, ERR_CRC);
            SendErrorTLV(MOD_SD, ST_ERR, ERR_CRC);
        }
        f_mount(NULL, (TCHAR const*)USERPath, 0);
        g_sd_mounted = 0;
        return;
    }

    // Kalau sebelumnya SD error lalu sekarang sukses, kirim status OK
    if (g_err_sd) {
        g_err_sd = 0;
        Debug_ErrorJson(MOD_SD, ST_OK, ERR_NONE);
        SendErrorTLV(MOD_SD, ST_OK, ERR_NONE);
    }

    // (Opsional) debug
    // UART_Print("[STATUS] status.json updated\r\n");
}

static float ParseFloatFromJSON(const char *str, const char *key) {
    const char *p = strstr(str, key);
    if (p) {
        p += strlen(key);
        return atof(p);
    }
    return 0.0f;
}

static bool Log_ParseJSONToMeasurement(const char *json, Measurement_t *m) {
    memset(m, 0, sizeof(Measurement_t));
    if (!JSON_ParseSeqFromLine(json, &m->seq)) return false;

    float temp = ParseFloatFromJSON(json, "\"temp\":");
    float hum = ParseFloatFromJSON(json, "\"hum\":");
    m->temp = (int16_t)(temp * 10.0f);
    m->hum = (int16_t)(hum * 10.0f);

    const char *p = strstr(json, "\"dig_in\":[");
    if (p) {
        p += 10;
        for (int i = 0; i < NUM_INPUTS_TOTAL; i++) {
            if (*p == '1') m->dig_in |= (1U << i);
            p++;
            if (*p == ',') p++;
            else if (*p == ']') break;
        }
    }

    p = strstr(json, "\"an_in\":[");
    if (p) {
        p += 9;
        for (int i = 0; i < NUM_ANALOG; i++) {
            int val;
            if (sscanf(p, "%d", &val) == 1) m->an_in[i] = (uint16_t)val;
            while (*p && *p != ',' && *p != ']') p++;
            if (*p == ',') p++;
        }
    }

    p = strstr(json, "\"q\":[");
    if (p) {
        p += 5;
        for (int i = 0; i < NUM_OUTPUTS; i++) {
            if (*p == '1') m->q |= (1U << i);
            p++;
            if (*p == ',') p++;
            else if (*p == ']') break;
        }
    }

    p = strstr(json, "\"timestamp\":\"");
    if (p) {
        p += 13;
        unsigned int Y, M, D, h, m_time, s;
        if (sscanf(p, "%04u-%02u-%02uT%02u:%02u:%02uZ", &Y, &M, &D, &h, &m_time, &s) == 6) {
            m->rtc.year = Y;
            m->rtc.month = M;
            m->rtc.day = D;
            m->rtc.hours = h;
            m->rtc.minutes = m_time;
            m->rtc.seconds = s;
            m->rtc.dayOfWeek = 1;
        }
    }
    return true;
}

static bool Log_GetFirstPendingMeasurement(Measurement_t *m) {
    if (!g_sd_mounted) return false;
    static FIL f;
    if (f_open(&f, LOG_FILE_NAME, FA_READ | FA_OPEN_EXISTING) != FR_OK) return false;

    static char line[JSON_LINE_MAX];
    bool found = false;
    while (f_gets(line, sizeof(line), &f) != NULL) {
        if (JSON_ParseSeqFromLine(line, &m->seq)) {
            Log_ParseJSONToMeasurement(line, m);
            found = true;
            break;
        }
    }
    f_close(&f);
    return found;
}

/* ==================== APPLICATION ==================== */
static void App_BackgroundSensors(uint32_t now)
{
    static uint8_t  initialized   = 0;
    static uint32_t lastDhtMs     = 0;
    static uint16_t stableMask    = 0;
    static uint16_t lastRawMask   = 0;
    static uint32_t lastChangeMs  = 0;
    static uint32_t lastRtcCheckMs = 0;

    if (!initialized)
    {
        uint16_t mask0 = 0;
        for (uint8_t i = 0; i < NUM_INPUTS; i++) {
            GPIO_PinState s = HAL_GPIO_ReadPin(g_inputs[i].Port, g_inputs[i].Pin);
            if (s == GPIO_PIN_RESET) mask0 |= (1 << i);
        }
        stableMask        = mask0;
        lastRawMask       = mask0;
        g_nativeInputMask = mask0;
        RecomputeCombinedInputMask();
        lastChangeMs      = now;
        lastDhtMs         = now - 2000U;
        initialized       = 1;
    }

    // Update temp/hum every 2s
    if ((now - lastDhtMs) >= 2000U)
    {
        float t_tmp, h_tmp;
        uint8_t ok = DHT22_Read(&t_tmp, &h_tmp);

        if (ok) {
            // Baca SUKSES
            g_temp = t_tmp;
            g_hum  = h_tmp;

            // Jika sebelumnya error, sekarang recover
            if (g_err_dht) {
                g_err_dht = 0;
                Debug_ErrorJson(MOD_DHT, ST_OK, ERR_NONE);
                SendErrorTLV(MOD_DHT, ST_OK, ERR_NONE);
            }
        } else {
            // Baca GAGAL , tunda pelaporan selama 5 detik
            if ((now - g_bootMs) >= DHT_ERROR_ENABLE_DELAY_MS) {
                if (!g_err_dht) {
                    g_err_dht = 1;
                    Debug_ErrorJson(MOD_DHT, ST_ERR, ERR_TIMEOUT);   // baca DHT timeout / gagal
                    SendErrorTLV(MOD_DHT, ST_ERR, ERR_TIMEOUT);
                }
            }
        }

        lastDhtMs = now;
    }

    // ADS background
    ADS_Task();

    // Read RAW inputs
    uint16_t rawMask = 0;
    for (uint8_t i = 0; i < NUM_INPUTS; i++) {
        GPIO_PinState s = HAL_GPIO_ReadPin(g_inputs[i].Port, g_inputs[i].Pin);
        if (s == GPIO_PIN_RESET) rawMask |= (1 << i);
    }

    if (rawMask != lastRawMask) {
        lastRawMask  = rawMask;
        lastChangeMs = now;
    }

    // Debounce 500 ms
    if ((rawMask != stableMask) && ((now - lastChangeMs) >= INPUT_CHANGE_TIME_MS))
    {
        stableMask        = rawMask;
        g_nativeInputMask = stableMask;
        RecomputeCombinedInputMask();
    }

    static uint32_t lastAppliedMask = 0xFFFFFFFFUL;
    if (g_inputMaskStable != lastAppliedMask || g_ruleUpdated)
    {
        ApplyRules(g_inputMaskStable);
        lastAppliedMask = g_inputMaskStable;
    }

    if (g_ruleUpdated)
    {
        PrintRuleStatus();
        g_ruleUpdated = 0;
    }

    /*Update RTC*/
    if ((now - lastRtcCheckMs) >= 2000U) {
        lastRtcCheckMs = now;

        DS3231_TimeTypeDef tmp;
        if (!DS3231_ReadTime(&tmp)) {
            if (!g_err_rtc) {
                g_err_rtc = 1;
                Debug_ErrorJson(MOD_RTC, ST_ERR, ERR_TIMEOUT);
                SendErrorTLV(MOD_RTC, ST_ERR, ERR_TIMEOUT);
            }
        } else {
            if (g_err_rtc) {
                g_err_rtc = 0;
                Debug_ErrorJson(MOD_RTC, ST_OK, ERR_NONE);
                SendErrorTLV(MOD_RTC, ST_OK, ERR_NONE);
            }
        }
    }
}

static void Acquire_FillMeasurement(Measurement_t *m, const DS3231_TimeTypeDef *rtc)
{
    m->seq = g_nextSeq;
    m->rtc = *rtc;

    m->temp = (int16_t)(g_temp * 10.0f);
    m->hum  = (int16_t)(g_hum * 10.0f);

    m->dig_in = g_inputMaskStable;

    for (int i = 0; i < 4; i++) {
        m->an_in[i] = (uint16_t)g_anCache[i];
    }

    m->q = 0;
    for (int i = 0; i < NUM_OUTPUTS; i++) {
        if (HAL_GPIO_ReadPin(g_outputs[i].Port, g_outputs[i].Pin) == GPIO_PIN_SET) {
            m->q |= (1U << i);
        }
    }
}

static void App_HandleAcquisition(uint32_t now)
{
    static uint32_t lastLogTick = 0;
    static uint8_t  initialized = 0;

    bool needLog = false;
    bool byIo    = false;

    // Inisialisasi pertama kali: mulai hitung interval dari waktu boot
    if (!initialized) {
        lastLogTick = now;
        initialized = 1;
    }

    // 1) Trigger: perubahan input (langsung kirim, reset interval)
    if (g_io_changed_flag) {
        g_io_changed_flag = 0;
        needLog = true;
        byIo    = true;
    }

    // 2) Periodik: tiap DELIVERY_TIME_INTERVAL (misalnya 60000 ms)
    if (!needLog && (now - lastLogTick) >= DELIVERY_TIME_INTERVAL) {
        needLog = true;
        byIo    = false;
    }

    if (!needLog) return;

    // Reset base waktu interval ke saat pengiriman ini
    lastLogTick = now;

    // ======= Di bawah ini biarkan persis seperti semula =======

    // 3) Baca RTC
    DS3231_TimeTypeDef rtc;
    if (!DS3231_ReadTime(&rtc)) {
        if (!g_err_rtc) {
            g_err_rtc = 1;
            Debug_ErrorJson(MOD_RTC, ST_ERR, ERR_TIMEOUT);
            SendErrorTLV(MOD_RTC, ST_ERR, ERR_TIMEOUT);
        }
        memset(&rtc, 0, sizeof(rtc));
        rtc.year  = 2000;
        rtc.month = 1;
        rtc.day   = 1;
    } else {
        if (g_err_rtc) {
            g_err_rtc = 0;
            Debug_ErrorJson(MOD_RTC, ST_OK, ERR_NONE);
            SendErrorTLV(MOD_RTC, ST_OK, ERR_NONE);
        }
    }

    // 4) Isi measurement
    Measurement_t m;
    Acquire_FillMeasurement(&m, &rtc);

    // 5) Encode JSON (untuk SD & debug)
    char  jsonLine[JSON_LINE_MAX];
    size_t jsonLen = JSON_EncodeMeasurement(&m, jsonLine, sizeof(jsonLine));
    if (jsonLen == 0) {
        DBG_PRINT("[ACQ] JSON encode failed\r\n");
        return;
    }

    // 6) Debug ke UART selalu (USART1)
    Debug_PrintMeasurementJSON(&m, byIo);

    // 7) Kalau SD ter-mount, simpan ke log.json
    if (g_sd_mounted) {
        if (Log_AppendJSON(jsonLine)) {
            g_pendingLogCount++;
        } else {
            DBG_PRINT("[ACQ] Log append failed\r\n");
        }
    } else {
        // SD tidak ter-mount: kalau TX idle, kirim langsung.
        // Kalau TX SEDANG SIBUK (mis. masih retry event lain), event ini
        // sebelumnya HILANG TOTAL tanpa jejak (tidak masuk log krn SD mati,
        // ditolak TX_StartNew krn busy). Sekarang ditahan dulu di buffer
        // RAM darurat, di-flush ke log.json begitu SD kembali ter-mount.
        if (g_txState == TX_STATE_IDLE) {
            TX_StartNew(&m);
        } else {
            Emergency_Push(&m);
        }
    }

    // 8) Naikkan seq + persist counter (independen dari isi queue,
    //    lihat penjelasan di Seq_Persist()). Frekuensi rendah (per
    //    perubahan IO / tiap 60s) jadi aman utk wear SD card.
    g_nextSeq++;
    Seq_Persist(g_nextSeq);
}

static void UART_ProcessPendingFrame(void) {
    /* Kuras semua slot yg tersedia tiap panggilan (maks DEFERRED_FRAME_SLOTS,
       jumlahnya kecil jadi aman dari sisi waktu eksekusi). Ini memastikan
       kalau beberapa frame sempat menumpuk saat boot (SD_MOUNT/LOG_RECOVER),
       begitu APP_STATE_RUN tercapai semuanya langsung diproses berurutan,
       bukan cuma 1 per loop iterasi. */
    while (g_deferredCount > 0) {
        uint8_t idx = g_deferredHead;
        OnFrameReceived((uint8_t*)g_deferredFrames[idx].buf,
                        g_deferredFrames[idx].len,
                        g_deferredFrames[idx].type);
        g_deferredHead = (g_deferredHead + 1) % DEFERRED_FRAME_SLOTS;

        __disable_irq();
        g_deferredCount--;
        __enable_irq();
    }

    if (g_deferredDroppedCount > 0) {
        DBG_PRINTF(
                 "[UART] %lu frame dibuang (ring buffer sempat penuh)\r\n",
                 (unsigned long)g_deferredDroppedCount);
        g_deferredDroppedCount = 0;
    }
}

/* ----------------------------------------------------------------------
   TX_StartNew()
   Dipanggil dari App_HandleAcquisition() SEBAGAI PENGGANTI panggilan
   langsung ke SendMeasurementTLV(&m). Tidak langsung kirim - hanya
   menyiapkan context dan menyerahkan eksekusi ke TX_Process() yang
   berjalan non-blocking tiap iterasi main loop.

   Kalau TX sebelumnya masih berjalan (state != IDLE), measurement baru
   TIDAK ditembak (supaya tidak menimpa context yang sedang retry/wait-ack).
   Data measurement yang baru tetap sudah aman di log.json (sudah dipanggil
   Log_AppendJSON sebelum titik ini di App_HandleAcquisition), jadi tidak
   ada data yang hilang - hanya pengiriman TLV-nya yang ditunda ke siklus
   App_HandleAcquisition berikutnya.
   ---------------------------------------------------------------------- */
static void TX_StartNew(const Measurement_t *m)
{
    if (g_txState != TX_STATE_IDLE)
    {
        DBG_PRINTF(
                 "[TX] busy (state=%d), seq=%lu tetap di log.json, kirim ditunda\r\n",
                 (int)g_txState, (unsigned long)m->seq);
        return;
    }

    g_txCtx.seq         = m->seq;
    g_txCtx.measurement = *m;          /* copy penuh, dipakai ulang saat retry */
    g_txCtx.retryCount  = 0;
    g_txCtx.jsonLen     = 0;           /* tidak dipakai di jalur TLV, dibiarkan utk kompatibilitas struct */

    g_txState = TX_STATE_SEND_FRAME;
}

/* ----------------------------------------------------------------------
   TX_Process()
   Dipanggil SETIAP iterasi while(1) di main(), tanpa blocking dan tanpa
   HAL_Delay di dalamnya. Mengeksekusi satu state per pemanggilan.

   Alur:
     IDLE            -> menunggu TX_StartNew() dipanggil
     SEND_FRAME      -> kirim TLV via SendMeasurementTLV (re-encode dari
                        g_txCtx.measurement, jadi retry kirim ulang frame
                        yang identik)
     WAIT_TX_COMPLETE-> (di implementasi ini SendMeasurementTLV blocking
                        HAL_UART_Transmit dengan timeout 200ms, sudah
                        cukup singkat - state ini dilewati langsung ke
                        WAIT_ACK. Disediakan di enum utk pengembangan
                        DMA/IT based transmit di masa depan)
     WAIT_ACK        -> polling g_ack_pending (diisi ISR USART2) sampai
                        match seq atau timeout ACK_TIMEOUT_MS
     ACK_OK          -> hapus baris log.json utk seq ini, balik ke IDLE
     RETRY_OR_FAIL   -> increment retryCount, ulang SEND_FRAME kalau
                        masih di bawah TX_MAX_RETRY, kalau tidak pindah
                        ke MOVE_TO_ERROR
     MOVE_TO_ERROR   -> log kegagalan permanen, data TETAP ada di
                        log.json (tidak dihapus - itulah keamanannya),
                        balik ke IDLE supaya measurement berikutnya
                        tidak ikut macet
   ---------------------------------------------------------------------- */
static void TX_Process(uint32_t now)
{
    switch (g_txState)
    {
    case TX_STATE_IDLE:
        if (g_sd_mounted && g_pendingLogCount > 0) {
            Measurement_t pendingM;
            if (Log_GetFirstPendingMeasurement(&pendingM)) {
                if (pendingM.seq == g_lastFailedSeq) {
                    if ((HAL_GetTick() - g_lastFailedTick) < 5000) {
                        break; // Tunggu 5 detik sebelum retry data yang gagal
                    }
                }
                TX_StartNew(&pendingM);
            } else {
                g_pendingLogCount = 0; // Sinkronisasi jika log kosong tapi count > 0
            }
        }
        break;

    case TX_STATE_SEND_FRAME:
        g_ack_pending = 0; // Hapus sisa ACK basi sebelum transmit baru
        if (SendMeasurementTLV(&g_txCtx.measurement))
        {
            g_txCtx.ackDeadlineMs = now + ACK_TIMEOUT_MS;
            g_txState = TX_STATE_WAIT_ACK;
        }
        else
        {
            /* UART_Transmit gagal (HAL_BUSY/HAL_ERROR) - kemungkinan
               line sedang dipakai. Langsung ke retry, bukan ke error,
               karena ini biasanya transient. */
            g_txState = TX_STATE_RETRY_OR_FAIL;
        }
        break;

    case TX_STATE_WAIT_TX_COMPLETE:
        /* Tidak dipakai pada implementasi UART blocking saat ini.
           Disediakan utk migrasi ke HAL_UART_Transmit_IT/DMA nanti -
           pada saat itu state ini menunggu callback TxCpltCallback
           sebelum lanjut ke WAIT_ACK. */
        g_txState = TX_STATE_WAIT_ACK;
        break;

    case TX_STATE_WAIT_ACK:
        if (g_ack_pending && g_ack_seq == g_txCtx.seq)
        {
            g_ack_pending = 0;
            g_txState = TX_STATE_ACK_OK;
        }
        else if ((int32_t)(now - g_txCtx.ackDeadlineMs) >= 0)
        {
            DBG_PRINTF(
                     "[TX] ACK timeout seq=%lu\r\n",
                     (unsigned long)g_txCtx.seq);
            g_txState = TX_STATE_RETRY_OR_FAIL;
        }
        /* kalau ACK datang dengan seq BERBEDA dari yang ditunggu,
           dibiarkan saja di sini - kemungkinan ACK basi dari frame
           sebelumnya yang sudah lewat timeout-nya sendiri. Dibuang
           secara implisit pada iterasi berikutnya karena g_ack_pending
           akan ditimpa ACK baru atau tetap stale (tidak match selamanya
           sampai ada ACK baru yang benar). */
        break;

    case TX_STATE_ACK_OK:
        if (g_sd_mounted)
        {
            bool removed = Log_RemoveSeq(g_txCtx.seq);
            DBG_PRINTF(
                     "[TX] ACK OK seq=%lu, log_removed=%s\r\n",
                     (unsigned long)g_txCtx.seq, removed ? "YES" : "NO");
        }
        else
        {
            DBG_PRINTF(
                     "[TX] ACK OK seq=%lu (no SD mounted)\r\n",
                     (unsigned long)g_txCtx.seq);
        }
        g_txState = TX_STATE_IDLE;
        break;

    case TX_STATE_RETRY_OR_FAIL:
        g_txCtx.retryCount++;
        if (g_txCtx.retryCount < TX_MAX_RETRY)
        {
            DBG_PRINTF(
                     "[TX] retry %u/%u seq=%lu\r\n",
                     g_txCtx.retryCount, TX_MAX_RETRY,
                     (unsigned long)g_txCtx.seq);
            g_txState = TX_STATE_SEND_FRAME;
        }
        else
        {
            g_txState = TX_STATE_MOVE_TO_ERROR;
        }
        break;

    case TX_STATE_MOVE_TO_ERROR:
        /* Data TIDAK dihapus dari log.json - itu poin pentingnya.
           Kegagalan kirim TLV ke ESP32 tidak berarti data hilang;
           tetap tersimpan di SD utk dikirim manual/recovery nanti.
           Kembali ke IDLE supaya measurement BERIKUTNYA (siklus
           App_HandleAcquisition selanjutnya) tidak ikut tersumbat
           oleh kegagalan yang sudah permanen ini. */
        DBG_PRINTF(
                 "[TX] FAILED permanen seq=%lu setelah %u retry, data tetap di log.json\r\n",
                 (unsigned long)g_txCtx.seq, TX_MAX_RETRY);

        g_lastFailedSeq = g_txCtx.seq;
        g_lastFailedTick = now;
        g_txState = TX_STATE_IDLE;
        break;

    default:
        g_txState = TX_STATE_IDLE;
        break;
    }
}

/* ==================== DEBUG ==================== */
static void Debug_ErrorJson(uint8_t mid, uint8_t st, uint8_t ec)
{
#if DEBUG_ENABLE
    // Format baru: {"mid":1,"st":1,"ec":2}
    DBG_PRINTF(
             "[ERR]{\"mid\":%u,\"st\":%u,\"ec\":%u}\r\n",
             mid, st, ec);
#else
    (void)mid; (void)st; (void)ec;
#endif
}

static void Debug_PrintMeasurementJSON(const Measurement_t *m, bool byIo)
{
    /* Fungsi ini murni dump JSON measurement ke UART1 utk monitoring
     * manusia (SD & TLV protokol dienkode terpisah, lihat JSON_EncodeMeasurement
     * & TLV_EncodeMeasurement) - seluruh isi di-strip saat DEBUG_ENABLE=0. */
#if DEBUG_ENABLE
    char ts[32];
    char digArr[64];
    char anArr[32];
    char qArr[24];
    char *p;
    int n;

    // Build timestamp
    snprintf(ts, sizeof(ts), "%04u-%02u-%02uT%02u:%02u:%02uZ",
             m->rtc.year, m->rtc.month, m->rtc.day,
             m->rtc.hours, m->rtc.minutes, m->rtc.seconds);

    // Build dig_in array (jumlah channel mengikuti Addon Type aktif)
    uint8_t digCount = Addon_ActiveInputCount();
    p = digArr;
    *p++ = '[';
    for (uint8_t i = 0; i < digCount; i++) {
        uint8_t bit = (m->dig_in & (1U << i)) ? 1 : 0;
        n = snprintf(p, sizeof(digArr) - (p - digArr), "%u%s",
                     bit, (i < digCount - 1) ? "," : "");
        if (n > 0) p += n;
    }
    *p++ = ']';
    *p = '\0';

    // Build an_in array
    snprintf(anArr, sizeof(anArr), "[%u,%u,%u,%u]",
             m->an_in[0], m->an_in[1], m->an_in[2], m->an_in[3]);

    // Build q array
    p = qArr;
    *p++ = '[';
    for (uint8_t i = 0; i < NUM_OUTPUTS; i++) {
        uint8_t bit = (m->q & (1U << i)) ? 1 : 0;
        n = snprintf(p, sizeof(qArr) - (p - qArr), "%u%s",
                     bit, (i < NUM_OUTPUTS - 1) ? "," : "");
        if (n > 0) p += n;
    }
    *p++ = ']';
    *p = '\0';

    const char *src = byIo ? "[ACQ][IO] " : "[ACQ][TMR] ";

    DBG_PRINTF(
        "%s{\"timestamp\":\"%s\",\"env\":{\"temp\":%.1f,\"hum\":%.1f},"
        "\"dig_in\":%s,\"an_in\":%s,\"q\":%s,\"seq\":%lu}\r\n",
        src, ts,
        m->temp / 10.0f, m->hum / 10.0f,
        digArr, anArr, qArr,
        (unsigned long)m->seq
    );
#else
    (void)m; (void)byIo;
#endif
}

/* ==================== TLV DEBUG DUMP ==================== */
static void Debug_DumpTLV(const char *prefix, const uint8_t *tlv, size_t len)
{
    /* Dump isi TLV mentah ke UART1 (dipakai opsional saat RX frame utk
     * troubleshooting - lihat pemanggilan yg di-comment di OnFrameReceived()).
     * Seluruh isi di-strip saat DEBUG_ENABLE=0. */
#if DEBUG_ENABLE
    size_t i = 0;

    DBG_PRINTF(
             "%s TLV dump, len=%u\r\n", prefix, (unsigned)len);

    while (i + 2 <= len)
    {
        uint8_t tag = tlv[i];
        uint8_t l   = tlv[i + 1];
        i += 2;

        if (i + l > len) {
            DBG_PRINTF(
                     "%s  !! malformed TLV (tag=0x%02X, len=%u, remaining=%u)\r\n",
                     prefix, tag, l, (unsigned)(len - (i - 2)));
            break;
        }

        int n = snprintf(g_debugBuf, sizeof(g_debugBuf),
                         "%s  tag=0x%02X len=%u val=", prefix, tag, l);
        for (uint8_t j = 0; j < l && n < (int)sizeof(g_debugBuf) - 3; j++) {
            n += snprintf(g_debugBuf + n, sizeof(g_debugBuf) - n,
                          "%02X ", tlv[i + j]);
        }
        snprintf(g_debugBuf + n, sizeof(g_debugBuf) - n, "\r\n");
        UART_Print(g_debugBuf);

        /* Interpretasi tag yang dikenal */
        if (tag == TLV_TAG_SEQ && l == 4) {
            uint32_t seq = TLV_ReadU32BE(&tlv[i]);
            DBG_PRINTF(
                     "%s    -> SEQ = %lu\r\n",
                     prefix, (unsigned long)seq);
        }
        else if (tag == TLV_TAG_TIMESTAMP && l == 4) {
            uint32_t ts = TLV_ReadU32BE(&tlv[i]);
            DBG_PRINTF(
                     "%s    -> TIMESTAMP = %lu (epoch)\r\n",
                     prefix, (unsigned long)ts);
        }
        else if (tag == TLV_TAG_TEMP && l == 2) {
            int16_t t = (int16_t)(((uint16_t)tlv[i] << 8) | tlv[i + 1]);
            DBG_PRINTF(
                     "%s    -> TEMP = %.1f C\r\n",
                     prefix, t / 10.0f);
        }
        else if (tag == TLV_TAG_HUM && l == 2) {
            int16_t h = (int16_t)(((uint16_t)tlv[i] << 8) | tlv[i + 1]);
            DBG_PRINTF(
                     "%s    -> HUM  = %.1f %%\r\n",
                     prefix, h / 10.0f);
        }
        else if (tag == TLV_TAG_DIG_IN && l == 2) {
            uint16_t dig = ((uint16_t)tlv[i] << 8) | tlv[i + 1];
            DBG_PRINTF(
                     "%s    -> DIG_IN mask = 0x%04X\r\n",
                     prefix, dig);
        }
        else if (tag == TLV_TAG_AN_IN && l == 8) {
            uint16_t an[4];
            for (int ch = 0; ch < 4; ch++) {
                an[ch] = ((uint16_t)tlv[i + ch*2] << 8) | tlv[i + ch*2 + 1];
            }
            DBG_PRINTF(
                     "%s    -> AN_IN = [%u,%u,%u,%u]\r\n",
                     prefix, an[0], an[1], an[2], an[3]);
        }
        else if (tag == TLV_TAG_Q && l == 1) {
            uint8_t q = tlv[i];
            DBG_PRINTF(
                     "%s    -> Q mask = 0x%02X\r\n",
                     prefix, q);
        }
        else if (tag == TAG_RULE) {   // dari ESP32
            DBG_PRINTF(
                     "%s    -> RULE string: \"%.*s\"\r\n",
                     prefix, l, (const char *)&tlv[i]);
        }
        else if (tag == TAG_RTC_TS && l == 4) {
            uint32_t epoch = TLV_ReadU32BE(&tlv[i]);
            DBG_PRINTF(
                     "%s    -> RTC EPOCH = %lu\r\n",
                     prefix, (unsigned long)epoch);
        }

        i += l;
    }
#else
    (void)prefix; (void)tlv; (void)len;
#endif
}

static void WD_Service(void)
{
    if (wd.sensor &&
        wd.acquisition &&
        wd.ack &&
        wd.tx &&
        wd.sd)
    {
        HAL_IWDG_Refresh(&hiwdg);

        wd.sensor = 0;
        wd.acquisition = 0;
        wd.ack = 0;
        wd.tx = 0;
        wd.sd = 0;
    }
}

/* USER CODE END 4 */

void Error_Handler(void)
{
  __disable_irq();
  while (1)
  {
  }
}
